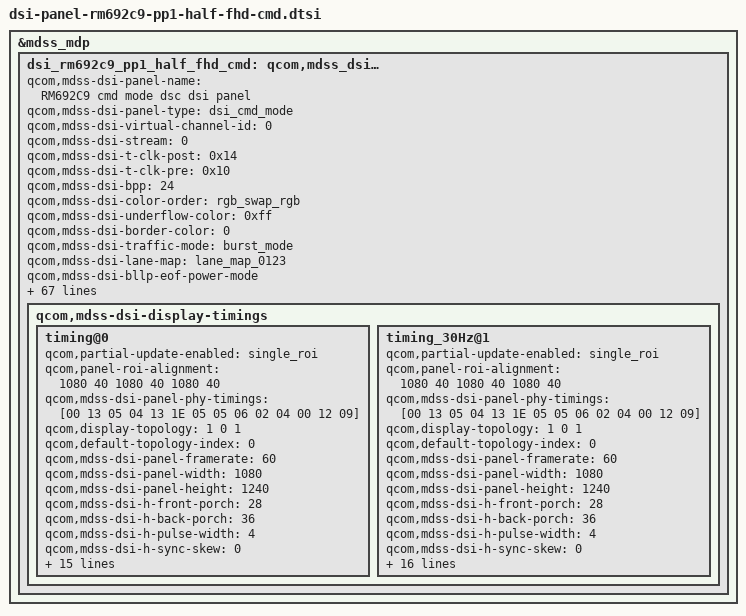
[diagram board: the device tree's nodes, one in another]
/* Copyright (c) 2014, Code Aurora Forum. All rights reserved.
 *
 * This program is free software; you can redistribute it and/or modify
 * it under the terms of the GNU General Public License version 2 and
 * only version 2 as published by the Free Software Foundation.
 *
 * This program is distributed in the hope that it will be useful,
 * but WITHOUT ANY WARRANTY; without even the implied warranty of
 * MERCHANTABILITY or FITNESS FOR A PARTICULAR PURPOSE.  See the
 * GNU General Public License for more details.
 */

&mdss_mdp {
    dsi_rm692c9_pp1_half_fhd_cmd: qcom,mdss_dsi_rm692c9_pp1_half_fhd_cmd {
		qcom,mdss-dsi-panel-name = "RM692C9 cmd mode dsc dsi panel";
		qcom,mdss-dsi-panel-type = "dsi_cmd_mode";
		qcom,mdss-dsi-virtual-channel-id = <0>;
		qcom,mdss-dsi-stream = <0>;
		qcom,mdss-dsi-t-clk-post = <0x14>;
		qcom,mdss-dsi-t-clk-pre = <0x10>;
		qcom,mdss-dsi-bpp = <24>;
		qcom,mdss-dsi-color-order = "rgb_swap_rgb";
		qcom,mdss-dsi-underflow-color = <0xff>;
		qcom,mdss-dsi-border-color = <0>;
		qcom,mdss-dsi-traffic-mode = "burst_mode";
		qcom,mdss-dsi-lane-map = "lane_map_0123";
		qcom,mdss-dsi-bllp-eof-power-mode;
		qcom,mdss-dsi-bllp-power-mode;
		qcom,mdss-dsi-lane-0-state;
		qcom,mdss-dsi-lane-1-state;
		qcom,mdss-dsi-lane-2-state;
		qcom,mdss-dsi-lane-3-state;
		qcom,mdss-dsi-reset-sequence = <1 10>, <0 2>, <1 10>;
		qcom,mdss-dsi-dma-trigger = "trigger_sw";
		qcom,mdss-dsi-mdp-trigger = "none";
		qcom,mdss-dsi-te-pin-select = <1>;
		qcom,panel-te-source = <1>;
		qcom,mdss-dsi-wr-mem-start = <0x2c>;
		qcom,mdss-dsi-wr-mem-continue = <0x3c>;
		qcom,mdss-dsi-te-dcs-command = <1>;
//		qcom,mdss-dsi-te-check-enable;
//		qcom,mdss-dsi-te-using-te-pin;
		qcom,mdss-dsi-lp11-init;
		qcom,mdss-dsi-tx-eot-append;
		qcom,dsi-sec-ctrl-num = <1>;
		qcom,dsi-sec-phy-num = <1>;
		/* qcom,dsi-select-sec-clocks = "src_byte_clk1", "src_pixel_clk1"; */
		qcom,dsi-select-sec-clocks = "mux_byte_clk1", "mux_pixel_clk1";
		qcom,ulps-enabled;
		//qcom,null-insertion-enabled;

		qcom,mdss-dsi-panel-hdr-enabled;
		qcom,mdss-dsi-panel-hdr-color-primaries = <14880 15935 32435 16555 14945 30910 7790 3415>;
		qcom,mdss-dsi-panel-peak-brightness = <5000000>;		/* max. 500nits */
		qcom,mdss-dsi-panel-blackness-level = <6134>;

		qcom,mdss-pan-physical-width-dimension = <69>;
		qcom,mdss-pan-physical-height-dimension = <80>;

		//lge,use-dim-ctrl;
		/* Brightness Map List */
		lge,blmap = <
			0
			9 9 9 9 9 9 9 9 9 9 9 10 10 10 10 11 11 11 11 12
			12 12 13 13 13 13 14 14 14 14 15 15 15 15 16 16 17 18 19 20
			22 23 24 25 26 27 28 29 31 32 33 34 35 36 37 38 40 41 42 43
			44 46 48 50 52 54 56 58 60 62 64 66 68 70 72 74 76 78 80 82
			84 87 90 93 92 95 98 101 104 107 111 114 117 120 123 126 129 132 135 138
			141 144 148 151 154 157 160 163 167 170 174 177 181 184 188 191 195 198 202 205
			209 213 216 220 223 227 230 234 237 241 244 248 251 255 260 266 271 276 281 287
			292 295 301 306 311 317 322 327 332 338 343 348 354 359 364 369 375 380 387 394
			400 407 413 420 426 433 439 446 452 459 466 472 479 485 492 498 505 511 518 524
			531 537 544 552 560 568 576 584 592 600 608 616 624 632 640 648 656 664 672 680
			688 696 704 712 720 728 736 746 756 765 775 785 795 805 814 824 834 844 854 863
			873 883 893 903 912 922 932 942 952 961 971 981 1027 1074 1120 1166 1213 1259 1305 1352
			1398 1444 1491 1537 1584 1630 1676 1723 1769 1815 1862 1908 1954 2001 2047 2047 2047 2047 2047 2047
			2047 2047 2047 2047 2047 2047 2047 2047 2047 2047 2047 2047 2047 2047 2047 2047 2047 2047 2047 2047
			2047 2047 2047 2047 2047 2047 2047 2047 2047 2047 2047 2047 2047 2047 2047 2047 2047 2047 2047 2047
			2047 2047 2047 2047 2047 2047 2047 2047 2047 2047 2047 2047 2047 2047 2047 2047 2047 2047 2047 2047
			2047 2047 2047 2047 2047 2047 2047 2047 2047 2047 2047 2047 2047 2047 2047 2047 2047 2047 2047 2047
			2047 2047 2047 2047 2047 2047 2047 2047 2047 2047 2047 2047 2047 2047 2047 2047 2047 2047 2047 2047
			2047 2047 2047 2047 2047
			>;
		lge,blmap-ve = <
			0
			9 9 9 9 9 9 9 9 9 9 9 10 10 10 10 11 11 11 11 12
			12 12 13 13 13 13 14 14 14 14 15 15 15 15 16 16 17 18 19 20
			22 23 24 25 26 27 28 29 31 32 33 34 35 36 37 38 40 41 42 43
			44 46 48 50 52 54 56 58 60 62 64 66 68 70 72 74 76 78 80 82
			84 87 90 93 92 95 98 101 104 107 111 114 117 120 123 126 129 132 135 138
			141 144 148 151 154 157 160 163 167 170 174 177 181 184 188 191 195 198 202 205
			209 213 216 220 223 227 230 234 237 241 244 248 251 255 260 266 271 276 281 287
			292 295 301 306 311 317 322 327 332 338 343 348 354 359 364 369 375 380 387 394
			400 407 413 420 426 433 439 446 452 459 466 472 479 485 492 498 505 511 518 524
			531 537 544 552 560 568 576 584 592 600 608 616 624 632 640 648 656 664 672 680
			688 696 704 712 720 728 736 746 756 765 775 785 795 805 814 824 834 844 854 863
			873 883 893 903 912 922 932 942 952 961 971 981 1027 1074 1120 1166 1213 1259 1305 1352
			1398 1444 1491 1537 1584 1630 1676 1723 1769 1815 1862 1908 1954 2001 2047 2047 2047 2047 2047 2047
			2047 2047 2047 2047 2047 2047 2047 2047 2047 2047 2047 2047 2047 2047 2047 2047 2047 2047 2047 2047
			2047 2047 2047 2047 2047 2047 2047 2047 2047 2047 2047 2047 2047 2047 2047 2047 2047 2047 2047 2047
			2047 2047 2047 2047 2047 2047 2047 2047 2047 2047 2047 2047 2047 2047 2047 2047 2047 2047 2047 2047
			2047 2047 2047 2047 2047 2047 2047 2047 2047 2047 2047 2047 2047 2047 2047 2047 2047 2047 2047 2047
			2047 2047 2047 2047 2047 2047 2047 2047 2047 2047 2047 2047 2047 2047 2047 2047 2047 2047 2047 2047
			2047 2047 2047 2047 2047
			>;
		lge,blmap-ex = <
			0
			16 16 16 16 16 16 16 16 16 20 24 28 32 37 41 45 49 53 57 61
			65 69 74 78 82 86 90 94 98 102 106 111 115 119 123 127 138 149 161 172
			183 194 205 217 228 239 250 261 273 284 295 306 317 329 340 351 362 374 385 396
			407 418 430 441 452 463 474 486 497 508 519 530 542 553 564 584 604 625 645 665
			685 706 726 746 766 787 807 827 847 867 888 908 928 948 969 989 1009 1026 1042 1059
			1075 1092 1108 1125 1141 1158 1174 1191 1207 1224 1240 1257 1273 1290 1306 1322 1337 1353 1368 1384
			1399 1415 1431 1446 1462 1477 1493 1509 1524 1540 1555 1571 1586 1602 1602 1602 1602 1602 1602 1602
			1625 1649 1672 1696 1719 1743 1766 1789 1813 1836 1860 1883 1906 1930 1953 1977 2000 2024 2047 2047
			2047 2047 2047 2047 2047 2047 2047 2047 2047 2047 2047 2047 2047 2047 2047 2047 2047 2047 2047 2047
			2047 2047 2047 2047 2047 2047 2047 2047 2047 2047 2047 2047 2047 2047 2047 2047 2047 2047 2047 2047
			2047 2047 2047 2047 2047 2047 2047 2047 2047 2047 2047 2047 2047 2047 2047 2047 2047 2047 2047 2047
			2047 2047 2047 2047 2047 2047 2047 2047 2047 2047 2047 2047 2047 2047 2047 2047 2047 2047 2047 2047
			2047 2047 2047 2047 2047 2047 2047 2047 2047 2047 2047 2047 2047 2047 2047
		>;
		lge,blmap-hdr = <
			0
			9 9 9 9 9 9 9 9 9 9 9 10 10 10 10 11 11 11 11 12
			12 12 13 13 13 13 14 14 14 14 15 15 15 15 16 16 17 18 19 20
			22 23 24 25 26 27 28 29 31 32 33 34 35 36 37 38 40 41 42 43
			44 46 48 50 52 54 56 58 60 62 64 66 68 70 72 74 76 78 80 82
			84 87 90 93 92 95 98 101 104 107 111 114 117 120 123 126 129 132 135 138
			141 144 148 151 154 157 160 163 167 170 174 177 181 184 188 191 195 198 202 205
			209 213 216 220 223 227 230 234 237 241 244 248 251 255 260 266 271 276 281 287
			292 295 301 306 311 317 322 327 332 338 343 348 354 359 364 369 375 380 387 394
			400 407 413 420 426 433 439 446 452 459 466 472 479 485 492 498 505 511 518 524
			531 537 544 552 560 568 576 584 592 600 608 616 624 632 640 648 656 664 672 680
			688 696 704 712 720 728 736 746 756 765 775 785 795 805 814 824 834 844 854 863
			873 883 893 903 912 922 932 942 952 961 971 981 1027 1074 1120 1166 1213 1259 1305 1352
			1398 1444 1491 1537 1584 1630 1676 1723 1769 1815 1862 1908 1954 2001 2047 2047 2047 2047 2047 2047
			2047 2047 2047 2047 2047 2047 2047 2047 2047 2047 2047 2047 2047 2047 2047 2047 2047 2047 2047 2047
			2047 2047 2047 2047 2047 2047 2047 2047 2047 2047 2047 2047 2047 2047 2047 2047 2047 2047 2047 2047
			2047 2047 2047 2047 2047 2047 2047 2047 2047 2047 2047 2047 2047 2047 2047 2047 2047 2047 2047 2047
			2047 2047 2047 2047 2047 2047 2047 2047 2047 2047 2047 2047 2047 2047 2047 2047 2047 2047 2047 2047
			2047 2047 2047 2047 2047 2047 2047 2047 2047 2047 2047 2047 2047 2047 2047 2047 2047 2047 2047 2047
			2047 2047 2047 2047 2047
		>;

		lge,use-color-manager;
		lge,use-color-manager-oled;

		lge,mdss-dsi-disp-ctrl-command-1 = [
			15 01 00 00 00 00 02 FE 00
		];
		lge,mdss-dsi-disp-ctrl-command-1-state = "dsi_lp_mode";
		lge,mdss-dsi-disp-ctrl-command-2 = [
			15 01 00 00 00 00 02 FE 00
		];
		lge,mdss-dsi-disp-ctrl-command-2-state = "dsi_lp_mode";

		lge,color-mode-cmds-dummy = [
			/* CE setting */
			15 00 00 00 00 00 02 FE 00
		];
		lge,color-mode-cmds-dummy-state = "dsi_lp_mode";

		//lge,use-color-manager-lut;
		lge,cm-lut-screen-mode-set-name = "def", "cin", "pho", "web", "spo", "gam", "exp";
		lge,cm-lut-screen-mode-set-cnt = <39>;
		lge,cm-lut-screen-mode-set = [
			00 0B 00 80 4F 44 20 EE 02 20 F0 CF 07 CF 04 F3 D7 CC 7D E3 07 10 FF 07 00 00 00 00 FF E7 00 03 20 00 FC 07 12 08 00
			00 0B 00 80 4F 00 FF FF 00 F0 EF C3 01 0F 0F 03 D2 EE 3F 85 07 10 53 07 08 3B 90 00 23 77 02 00 90 00 9F 06 12 00 00
			00 0B 00 80 4F F0 F0 C0 C0 22 F2 55 07 1F 00 03 43 00 EF 01 0C 10 FF 07 00 35 90 06 BD 46 02 28 80 03 46 06 12 00 00
			00 0B 00 80 4F F0 FF F0 00 FF FF D1 00 0F 0F 03 02 00 1F 05 04 10 0D 56 1E 36 F0 04 E1 36 02 1D 00 08 07 06 12 00 00
			00 0B 00 80 4F 46 22 EE 15 21 F0 CF 07 CF 04 F3 C7 CC 7D E3 07 10 2E 07 00 00 00 00 40 E7 00 03 30 00 FB 07 12 00 00
			00 0B 00 80 4F 46 40 FE 12 21 F0 CF 07 CF 04 F3 C7 CC 7D E3 07 10 7F 07 00 00 00 00 95 D7 00 03 30 00 FA 07 12 00 00
			00 0B 00 80 4F 44 20 EE 02 20 F0 CF 07 CF 04 F3 D7 CC 7D E3 07 10 FF 07 00 00 00 00 FF E7 00 03 20 00 FC 07 12 08 00
		];

		lge,cm-lut-saturation-cnt = <13>;
		lge,cm-lut-saturation = [
			00 0B 00 80 4F D9 DD DC DD DD CD 01 00
			00 0B 00 80 4F EC EF FE FF FF DF 01 00
			00 0B 00 80 4F 44 20 EE 02 20 F0 CF 07
			00 0B 00 80 4F FF 44 FF 23 44 B2 CD 0F
			00 0B 00 80 4F 1F 56 01 56 56 F3 FF 0F
		];

		lge,cm-lut-sharpness-cnt = <1>;
		lge,cm-lut-sharpness = [08 12 1C 26 30];

		lge,cm-lut-rgb-hue-cnt = <14>;
		lge,cm-lut-rgb-hue = [
			E0 25 01 F5 20 09 72 47 00 01 00 0C 50 06
			80 26 01 F5 20 09 72 A7 00 01 00 0C C0 06
			F0 26 01 F5 20 09 73 07 00 01 00 0C 40 07
			FF 26 01 F5 20 09 11 87 00 01 00 0C 3A 07
			FF 26 01 F5 20 09 7F 86 00 01 00 0C 30 07
			5A 06 01 7E 00 05 B8 47 00 00 F0 05 A4 06
			E8 06 01 7E 00 05 CF A7 00 00 F0 05 17 07
			68 07 01 7E 00 05 B9 07 00 00 F0 05 A3 07
			30 07 01 7E 00 05 00 87 00 00 F0 05 4F 07
			30 07 01 7E 00 05 84 96 00 00 F0 05 3F 07
			EB 06 00 00 00 00 FF 67 00 00 30 00 04 07
			77 07 00 00 00 00 FF 77 00 01 30 00 7C 07
			FF 07 00 00 00 00 FF E7 00 03 20 00 FC 07
			FF 07 00 00 00 00 9B 77 00 01 30 00 F4 07
			FF 07 00 00 00 00 21 87 00 01 30 00 F4 07
			35 06 0A 00 40 01 8F 67 04 43 E0 00 99 06
			C0 06 0A 00 40 01 8F 77 04 43 E0 00 10 07
			60 07 0A 00 40 01 8F E7 04 43 E0 00 B0 07
			60 07 0A 00 40 01 50 77 04 43 E0 00 AF 07
			60 07 0A 00 40 01 DE 76 04 43 E0 00 A7 07
			BA 75 12 00 F0 00 5D 67 08 7F E0 00 69 06
			4A 76 12 00 F0 00 5D 77 08 7F E0 00 DE 06
			EA 76 12 00 F0 00 5D E7 08 7F E0 00 73 07
			EA 76 12 00 F0 00 16 77 08 7F E0 00 70 07
			EA 76 12 00 F0 00 97 76 08 7F E0 00 6A 07
		];

		/* Video Enahnacement */
		lge,mdss-dsi-ve-on-command = [
			15 01 00 00 00 00 02 FE 00
		];
		lge,mdss-dsi-ve-on-command-state = "dsi_lp_mode";

		lge,mdss-dsi-ve-off-command = [
			15 01 00 00 00 00 02 FE 00
		];
		lge,mdss-dsi-ve-off-command-state = "dsi_lp_mode";

		qcom,mdss-dsi-display-timings {
			timing@0{
				qcom,partial-update-enabled = "single_roi";
				qcom,panel-roi-alignment = <1080 40 1080 40 1080 40>;
				qcom,mdss-dsi-panel-phy-timings = [00 13 05 04 13 1E 05 05 06 02 04 00 12 09];
				//qcom,mdss-dsi-panel-clockrate = <435355200>;
				qcom,display-topology = <1 0 1>;
				qcom,default-topology-index = <0>;
				qcom,mdss-dsi-panel-framerate = <60>;
				qcom,mdss-dsi-panel-width = <1080>;
				qcom,mdss-dsi-panel-height = <1240>;
				qcom,mdss-dsi-h-front-porch = <28>;
				qcom,mdss-dsi-h-back-porch = <36>;
				qcom,mdss-dsi-h-pulse-width = <4>;
				qcom,mdss-dsi-h-sync-skew = <0>;
				qcom,mdss-dsi-v-back-porch = <8>;
				qcom,mdss-dsi-v-front-porch = <16>;
				qcom,mdss-dsi-v-pulse-width = <4>;
				qcom,mdss-dsi-h-left-border = <0>;
				qcom,mdss-dsi-h-right-border = <0>;
				qcom,mdss-dsi-v-top-border = <0>;
				qcom,mdss-dsi-v-bottom-border = <0>;
				qcom,mdss-dsi-h-sync-pulse = <0>;
				//qcom,mdss-mdp-transfer-time-us = <15000>;

				qcom,mdss-dsi-on-command = [
					15 00 00 00 00 00 02 FE 40
					15 00 00 00 00 00 02 05 10
					15 00 00 00 00 00 02 06 0C
					15 00 00 00 00 00 02 08 0F
					15 00 00 00 00 00 02 09 0D
					15 00 00 00 00 00 02 0A 48
					15 00 00 00 00 00 02 0B AA
					15 00 00 00 00 00 02 0C 48
					15 00 00 00 00 00 02 0D 18
					15 00 00 00 00 00 02 0E 00
					15 00 00 00 00 00 02 0F 4D
					15 00 00 00 00 00 02 16 00
					15 00 00 00 00 00 02 20 87
					15 00 00 00 00 00 02 21 87
					15 00 00 00 00 00 02 24 00
					15 00 00 00 00 00 02 26 00
					15 00 00 00 00 00 02 28 00
					15 00 00 00 00 00 02 2A 00
					15 00 00 00 00 00 02 2D 28
					15 00 00 00 00 00 02 2F 28
					15 00 00 00 00 00 02 37 A0
					15 00 00 00 00 00 02 38 A0
					15 00 00 00 00 00 02 46 39
					15 00 00 00 00 00 02 47 39
					15 00 00 00 00 00 02 4C 08
					15 01 00 00 00 00 02 FE 00
					15 00 00 00 00 00 02 FE 40
					15 00 00 00 00 00 02 3B 20
					15 00 00 00 00 00 02 6B 40
					15 01 00 00 00 00 02 FE 00
					15 00 00 00 00 00 02 FE 70
					15 00 00 00 00 00 02 35 01
					15 01 00 00 00 00 02 FE 00
					15 00 00 00 00 00 02 FE 40
					15 00 00 00 00 00 02 4D 33
					15 00 00 00 00 00 02 4E 03
					15 00 00 00 00 00 02 6F 00
					15 00 00 00 00 00 02 A2 1A
					15 00 00 00 00 00 02 A3 1D
					15 00 00 00 00 00 02 D1 04
					15 00 00 00 00 00 02 D2 64
					15 01 00 00 00 00 02 FE 00
					15 00 00 00 00 00 02 FE 72
					15 00 00 00 00 00 02 69 FF
					15 01 00 00 00 00 02 FE 00
					15 00 00 00 00 00 02 FE 40
					15 00 00 00 00 00 02 74 51
					15 00 00 00 00 00 02 75 23
					15 00 00 00 00 00 02 80 48
					15 00 00 00 00 00 02 82 10
					15 01 00 00 00 00 02 FE 00
					15 00 00 00 00 00 02 FE 40
					15 00 00 00 00 00 02 84 01
					15 00 00 00 00 00 02 86 0F
					15 00 00 00 00 00 02 87 0D
					15 00 00 00 00 00 02 88 26
					15 00 00 00 00 00 02 89 26
					15 00 00 00 00 00 02 8B 00
					15 00 00 00 00 00 02 8C 00
					15 00 00 00 00 00 02 90 00
					15 00 00 00 00 00 02 91 06
					15 00 00 00 00 00 02 95 00
					15 00 00 00 00 00 02 9F 00
					15 00 00 00 00 00 02 A0 00
					15 01 00 00 00 00 02 FE 00
					15 00 00 00 00 00 02 FE A0
					15 00 00 00 00 00 02 45 B4
					15 01 00 00 00 00 02 FE 00
					15 00 00 00 00 00 02 FE 50
					15 00 00 00 00 00 02 E2 90
					15 00 00 00 00 00 02 E3 B0
					15 00 00 00 00 00 02 E4 1F
					15 00 00 00 00 00 02 E5 11
					15 00 00 00 00 00 02 E6 10
					15 00 00 00 00 00 02 E7 A0
					15 01 00 00 00 00 02 FE 00
					15 00 00 00 00 00 02 FE 52
					15 00 00 00 00 00 02 E2 90
					15 00 00 00 00 00 02 E3 B0
					15 00 00 00 00 00 02 E4 1F
					15 00 00 00 00 00 02 E5 11
					15 00 00 00 00 00 02 E6 10
					15 00 00 00 00 00 02 E7 A0
					15 01 00 00 00 00 02 FE 00
					15 00 00 00 00 00 02 FE 54
					15 00 00 00 00 00 02 E2 90
					15 00 00 00 00 00 02 E3 B0
					15 00 00 00 00 00 02 E4 1F
					15 00 00 00 00 00 02 E5 11
					15 00 00 00 00 00 02 E6 10
					15 00 00 00 00 00 02 E7 A0
					15 01 00 00 00 00 02 FE 00
					15 00 00 00 00 00 02 FE 56
					15 00 00 00 00 00 02 E2 90
					15 00 00 00 00 00 02 E3 B0
					15 00 00 00 00 00 02 E4 1F
					15 00 00 00 00 00 02 E5 11
					15 00 00 00 00 00 02 E6 10
					15 00 00 00 00 00 02 E7 A0
					15 01 00 00 00 00 02 FE 00
					15 00 00 00 00 00 02 FE A0
					15 00 00 00 00 00 02 0A 63
					15 01 00 00 00 00 02 FE 00
					15 00 00 00 00 00 02 FE 60
					15 00 00 00 00 00 02 EF 03
					15 00 00 00 00 00 02 F0 00
					15 00 00 00 00 00 02 F2 00
					15 00 00 00 00 00 02 F3 00
					15 00 00 00 00 00 02 F4 00
					15 01 00 00 00 00 02 FE 00
					15 00 00 00 00 00 02 FE D0
					15 00 00 00 00 00 02 43 01
					15 00 00 00 00 00 02 45 01
					15 01 00 00 00 00 02 FE 00
					15 00 00 00 00 00 02 FE 60
					15 00 00 00 00 00 02 00 84
					15 00 00 00 00 00 02 01 00
					15 00 00 00 00 00 02 02 00
					15 00 00 00 00 00 02 03 05
					15 00 00 00 00 00 02 04 00
					15 00 00 00 00 00 02 05 06
					15 00 00 00 00 00 02 06 79
					15 00 00 00 00 00 02 07 79
					15 00 00 00 00 00 02 09 C4
					15 00 00 00 00 00 02 0A 00
					15 00 00 00 00 00 02 0B 02
					15 00 00 00 00 00 02 0C 01
					15 00 00 00 00 00 02 0D 00
					15 00 00 00 00 00 02 0E 06
					15 00 00 00 00 00 02 0F 79
					15 00 00 00 00 00 02 10 0D
					15 00 00 00 00 00 02 12 C4
					15 00 00 00 00 00 02 13 00
					15 00 00 00 00 00 02 14 02
					15 00 00 00 00 00 02 15 01
					15 00 00 00 00 00 02 16 00
					15 00 00 00 00 00 02 17 03
					15 00 00 00 00 00 02 18 79
					15 00 00 00 00 00 02 19 0D
					15 00 00 00 00 00 02 1B C4
					15 00 00 00 00 00 02 1C 00
					15 00 00 00 00 00 02 1D 04
					15 00 00 00 00 00 02 1E 02
					15 00 00 00 00 00 02 1F 00
					15 00 00 00 00 00 02 20 00
					15 00 00 00 00 00 02 21 79
					15 00 00 00 00 00 02 22 00
					15 00 00 00 00 00 02 24 C4
					15 00 00 00 00 00 02 25 00
					15 00 00 00 00 00 02 26 04
					15 00 00 00 00 00 02 27 02
					15 00 00 00 00 00 02 28 00
					15 00 00 00 00 00 02 29 02
					15 00 00 00 00 00 02 2A 79
					15 00 00 00 00 00 02 2B 00
					15 00 00 00 00 00 02 95 CA
					15 00 00 00 00 00 02 96 00
					15 00 00 00 00 00 02 97 00
					15 00 00 00 00 00 02 98 00
					15 00 00 00 00 00 02 99 00
					15 00 00 00 00 00 02 9A 08
					15 00 00 00 00 00 02 9B 79
					15 00 00 00 00 00 02 9C 79
					15 00 00 00 00 00 02 9D 80
					15 01 00 00 00 00 02 FE 00
					15 00 00 00 00 00 02 FE 72
					15 00 00 00 00 00 02 21 00
					15 00 00 00 00 00 02 22 0A
					15 00 00 00 00 00 02 6D 0A
					15 00 00 00 00 00 02 B0 04
					15 00 00 00 00 00 02 B1 F4
					15 00 00 00 00 00 02 B2 04
					15 00 00 00 00 00 02 B3 F4
					15 00 00 00 00 00 02 4B B7
					15 00 00 00 00 00 02 6B B1
					15 00 00 00 00 00 02 AF FF
					15 00 00 00 00 00 02 FE 60
					15 00 00 00 00 00 02 C7 1F
					15 00 00 00 00 00 02 C8 17
					15 00 00 00 00 00 02 C9 16
					15 00 00 00 00 00 02 CA 02
					15 00 00 00 00 00 02 CB 01
					15 00 00 00 00 00 02 CC 10
					15 00 00 00 00 00 02 CD 04
					15 00 00 00 00 00 02 CE 03
					15 00 00 00 00 00 02 CF 1F
					15 00 00 00 00 00 02 D1 1F
					15 00 00 00 00 00 02 D2 1F
					15 00 00 00 00 00 02 D4 1F
					15 00 00 00 00 00 02 D5 1F
					15 00 00 00 00 00 02 DB 1F
					15 00 00 00 00 00 02 DC 17
					15 00 00 00 00 00 02 DD 16
					15 00 00 00 00 00 02 DE 02
					15 00 00 00 00 00 02 DF 01
					15 00 00 00 00 00 02 E0 00
					15 00 00 00 00 00 02 E1 04
					15 00 00 00 00 00 02 E2 03
					15 00 00 00 00 00 02 F5 80
					15 01 00 00 00 00 02 FE 00
					15 00 00 00 00 00 02 FE 70
					15 00 00 00 00 00 02 71 01
					15 00 00 00 00 00 02 72 30
					15 00 00 00 00 00 02 C3 82
					15 01 00 00 00 00 02 FE 00
					15 00 00 00 00 00 02 FE 72
					15 00 00 00 00 00 02 4B B7
					15 00 00 00 00 00 02 4C 4A
					15 00 00 00 00 00 02 4D 45
					15 00 00 00 00 00 02 52 0F
					15 00 00 00 00 00 02 6F 03
					15 00 00 00 00 00 02 8A 00
					15 00 00 00 00 00 02 8B 0A
					15 00 00 00 00 00 02 8C 15
					15 00 00 00 00 00 02 8D 18
					15 00 00 00 00 00 02 8E 4A
					15 00 00 00 00 00 02 8F 7E
					15 00 00 00 00 00 02 90 D4
					15 00 00 00 00 00 02 91 62
					15 00 00 00 00 00 02 92 28
					15 00 00 00 00 00 02 93 9A
					15 00 00 00 00 00 02 94 12
					15 00 00 00 00 00 02 95 62
					15 00 00 00 00 00 02 96 A8
					15 00 00 00 00 00 02 97 E8
					15 00 00 00 00 00 02 98 FF
					15 00 00 00 00 00 02 86 00
					15 00 00 00 00 00 02 87 40
					15 00 00 00 00 00 02 88 FA
					15 00 00 00 00 00 02 89 3F
					15 00 00 00 00 00 02 9D 11
					15 00 00 00 00 00 02 9E 16
					15 00 00 00 00 00 02 9F 17
					15 00 00 00 00 00 02 A0 18
					15 00 00 00 00 00 02 A2 21
					15 00 00 00 00 00 02 A3 36
					15 00 00 00 00 00 02 A4 5A
					15 00 00 00 00 00 02 A5 A2
					15 00 00 00 00 00 02 A6 22
					15 00 00 00 00 00 02 A7 A4
					15 00 00 00 00 00 02 A9 1F
					15 00 00 00 00 00 02 AA A1
					15 00 00 00 00 00 02 AB 1A
					15 00 00 00 00 00 02 AC 92
					15 00 00 00 00 00 02 AD FF
					15 00 00 00 00 00 02 99 00
					15 00 00 00 00 00 02 9A 00
					15 00 00 00 00 00 02 9B A5
					15 00 00 00 00 00 02 9C 3F
					15 00 00 00 00 00 02 FE 72
					15 00 00 00 00 00 02 77 00
					15 00 00 00 00 00 02 78 59
					15 00 00 00 00 00 02 79 B0
					15 00 00 00 00 00 02 7A BB
					15 00 00 00 00 00 02 7B DD
					15 00 00 00 00 00 02 7C E5
					15 00 00 00 00 00 02 7D 36
					15 00 00 00 00 00 02 7E 97
					15 00 00 00 00 00 02 7F 30
					15 00 00 00 00 00 02 80 9D
					15 00 00 00 00 00 02 81 F6
					15 00 00 00 00 00 02 82 45
					15 00 00 00 00 00 02 83 8A
					15 00 00 00 00 00 02 84 CE
					15 00 00 00 00 00 02 85 FF
					15 00 00 00 00 00 02 73 00
					15 00 00 00 00 00 02 74 50
					15 00 00 00 00 00 02 75 EA
					15 00 00 00 00 00 02 76 3F
					15 01 00 00 00 00 02 FE 00
					15 00 00 00 00 00 02 FE 74
					15 00 00 00 00 00 02 00 00
					15 00 00 00 00 00 02 01 00
					15 00 00 00 00 00 02 02 41
					15 00 00 00 00 00 02 03 07
					15 00 00 00 00 00 02 04 0F
					15 00 00 00 00 00 02 05 00
					15 00 00 00 00 00 02 06 00
					15 00 00 00 00 00 02 07 00
					15 00 00 00 00 00 02 08 00
					15 00 00 00 00 00 02 09 30
					15 00 00 00 00 00 02 0A C2
					15 00 00 00 00 00 02 0B FF
					15 00 00 00 00 00 02 0C 00
					15 00 00 00 00 00 02 0D FF
					15 01 00 00 00 00 02 FE 00
					15 00 00 00 00 00 02 FE 74
					15 00 00 00 00 00 02 0E 70
					15 00 00 00 00 00 02 0F 00
					15 00 00 00 00 00 02 10 02
					15 00 00 00 00 00 02 11 00
					15 00 00 00 00 00 02 12 00
					15 00 00 00 00 00 02 13 00
					15 00 00 00 00 00 02 14 00
					15 00 00 00 00 00 02 15 02
					15 00 00 00 00 00 02 16 06
					15 00 00 00 00 00 02 17 01
					15 00 00 00 00 00 02 18 00
					15 00 00 00 00 00 02 19 07
					15 00 00 00 00 00 02 1A 00
					15 00 00 00 00 00 02 1B 00
					15 00 00 00 00 00 02 1C 00
					15 00 00 00 00 00 02 1D 00
					15 00 00 00 00 00 02 1E 00
					15 00 00 00 00 00 02 1F 00
					15 00 00 00 00 00 02 20 00
					15 00 00 00 00 00 02 21 00
					15 00 00 00 00 00 02 22 10
					15 00 00 00 00 00 02 23 00
					15 00 00 00 00 00 02 24 F0
					15 00 00 00 00 00 02 25 FF
					15 00 00 00 00 00 02 26 FF
					15 00 00 00 00 00 02 27 FF
					15 00 00 00 00 00 02 28 FF
					15 00 00 00 00 00 02 29 00
					15 00 00 00 00 00 02 2A FF
					15 00 00 00 00 00 02 2B FF
					15 00 00 00 00 00 02 2D FF
					15 00 00 00 00 00 02 2F FF
					15 00 00 00 00 00 02 30 FF
					15 00 00 00 00 00 02 31 FF
					15 00 00 00 00 00 02 32 FF
					15 00 00 00 00 00 02 33 FF
					15 00 00 00 00 00 02 34 FF
					15 00 00 00 00 00 02 35 FF
					15 00 00 00 00 00 02 36 FF
					15 00 00 00 00 00 02 37 FF
					15 00 00 00 00 00 02 38 FF
					15 00 00 00 00 00 02 39 FF
					15 00 00 00 00 00 02 3A FF
					15 00 00 00 00 00 02 3B FF
					15 00 00 00 00 00 02 3D FF
					15 00 00 00 00 00 02 3F FF
					15 00 00 00 00 00 02 40 FF
					15 00 00 00 00 00 02 41 FF
					15 00 00 00 00 00 02 42 FF
					15 00 00 00 00 00 02 43 30
					15 00 00 00 00 00 02 44 00
					15 00 00 00 00 00 02 45 F3
					15 00 00 00 00 00 02 46 FF
					15 00 00 00 00 00 02 47 3F
					15 00 00 00 00 00 02 48 FF
					15 00 00 00 00 00 02 49 FF
					15 00 00 00 00 00 02 4A FF
					15 00 00 00 00 00 02 4B FF
					15 00 00 00 00 00 02 4C FF
					15 00 00 00 00 00 02 4D FF
					15 00 00 00 00 00 02 4E FF
					15 00 00 00 00 00 02 4F FF
					15 00 00 00 00 00 02 50 FF
					15 00 00 00 00 00 02 51 FF
					15 00 00 00 00 00 02 52 FF
					15 00 00 00 00 00 02 53 FF
					15 00 00 00 00 00 02 54 FF
					15 00 00 00 00 00 02 55 FF
					15 00 00 00 00 00 02 56 FF
					15 00 00 00 00 00 02 58 FF
					15 00 00 00 00 00 02 59 FF
					15 00 00 00 00 00 02 5A FF
					15 00 00 00 00 00 02 5B FF
					15 00 00 00 00 00 02 5C FF
					15 00 00 00 00 00 02 5D FF
					15 00 00 00 00 00 02 5E FF
					15 00 00 00 00 00 02 5F FF
					15 00 00 00 00 00 02 60 FF
					15 00 00 00 00 00 02 61 70
					15 00 00 00 00 00 02 62 00
					15 00 00 00 00 00 02 63 FF
					15 00 00 00 00 00 02 64 FF
					15 00 00 00 00 00 02 65 FF
					15 00 00 00 00 00 02 66 FF
					15 00 00 00 00 00 02 67 FF
					15 00 00 00 00 00 02 68 FF
					15 00 00 00 00 00 02 69 FF
					15 00 00 00 00 00 02 6A FF
					15 00 00 00 00 00 02 6B FF
					15 00 00 00 00 00 02 6C FF
					15 00 00 00 00 00 02 6D FF
					15 00 00 00 00 00 02 6E FF
					15 00 00 00 00 00 02 6F FF
					15 00 00 00 00 00 02 70 FF
					15 00 00 00 00 00 02 71 FF
					15 00 00 00 00 00 02 72 FF
					15 00 00 00 00 00 02 73 FF
					15 00 00 00 00 00 02 74 FF
					15 00 00 00 00 00 02 75 FF
					15 00 00 00 00 00 02 76 FF
					15 00 00 00 00 00 02 77 FF
					15 00 00 00 00 00 02 78 FF
					15 00 00 00 00 00 02 79 FF
					15 00 00 00 00 00 02 7A FF
					15 00 00 00 00 00 02 7B FF
					15 00 00 00 00 00 02 7C FF
					15 00 00 00 00 00 02 7D FF
					15 01 00 00 00 00 02 FE 00
					15 00 00 00 00 00 02 FE 90
					15 00 00 00 00 00 02 00 86
					15 00 00 00 00 00 02 01 61
					15 00 00 00 00 00 02 02 18
					15 00 00 00 00 00 02 03 24
					15 00 00 00 00 00 02 04 49
					15 00 00 00 00 00 02 05 92
					15 00 00 00 00 00 02 06 86
					15 00 00 00 00 00 02 07 61
					15 00 00 00 00 00 02 08 18
					15 00 00 00 00 00 02 09 24
					15 00 00 00 00 00 02 0A 49
					15 00 00 00 00 00 02 0B 92
					15 00 00 00 00 00 02 0C 86
					15 00 00 00 00 00 02 0D 61
					15 00 00 00 00 00 02 0E 18
					15 00 00 00 00 00 02 0F 24
					15 00 00 00 00 00 02 10 49
					15 00 00 00 00 00 02 11 92
					15 01 00 00 00 00 02 FE 00
					15 00 00 00 00 00 02 FE 40
					15 00 00 00 00 00 02 85 17
					15 01 00 00 00 00 02 FE 00
					15 00 00 00 00 00 02 FE 90
					15 00 00 00 00 00 02 14 70
					15 00 00 00 00 00 02 15 E1
					15 00 00 00 00 00 02 16 97
					15 00 00 00 00 00 02 13 31
					15 00 00 00 00 00 02 18 50
					15 00 00 00 00 00 02 19 14
					15 00 00 00 00 00 02 1A 40
					15 00 00 00 00 00 02 1B 60
					15 00 00 00 00 00 02 2A C1
					15 00 00 00 00 00 02 1C 21
					15 00 00 00 00 00 02 1D 21
					15 00 00 00 00 00 02 1E 21
					15 00 00 00 00 00 02 1F 21
					15 00 00 00 00 00 02 20 00
					15 00 00 00 00 00 02 21 00
					15 00 00 00 00 00 02 22 00
					15 00 00 00 00 00 02 2B 10
					15 00 00 00 00 00 02 2D 60
					15 00 00 00 00 00 02 2F 10
					15 00 00 00 00 00 02 30 30
					15 00 00 00 00 00 02 31 08
					15 00 00 00 00 00 02 32 60
					15 00 00 00 00 00 02 33 20
					15 00 00 00 00 00 02 34 50
					15 00 00 00 00 00 02 35 30
					15 00 00 00 00 00 02 36 40
					15 00 00 00 00 00 02 37 40
					15 00 00 00 00 00 02 38 30
					15 00 00 00 00 00 02 39 50
					15 00 00 00 00 00 02 3A 20
					15 00 00 00 00 00 02 3B 60
					15 00 00 00 00 00 02 3D 08
					15 00 00 00 00 00 02 3F 10
					15 00 00 00 00 00 02 40 60
					15 00 00 00 00 00 02 41 10
					15 00 00 00 00 00 02 42 30
					15 00 00 00 00 00 02 43 08
					15 00 00 00 00 00 02 44 60
					15 00 00 00 00 00 02 45 20
					15 00 00 00 00 00 02 46 50
					15 00 00 00 00 00 02 47 30
					15 00 00 00 00 00 02 48 40
					15 00 00 00 00 00 02 49 40
					15 00 00 00 00 00 02 4A 30
					15 00 00 00 00 00 02 4B 50
					15 00 00 00 00 00 02 4C 20
					15 00 00 00 00 00 02 4D 60
					15 00 00 00 00 00 02 4E 08
					15 00 00 00 00 00 02 4F 10
					15 00 00 00 00 00 02 50 60
					15 00 00 00 00 00 02 51 10
					15 00 00 00 00 00 02 52 15
					15 00 00 00 00 00 02 53 56
					15 00 00 00 00 00 02 54 15
					15 00 00 00 00 00 02 55 00
					15 00 00 00 00 00 02 56 15
					15 00 00 00 00 00 02 58 56
					15 00 00 00 00 00 02 59 15
					15 00 00 00 00 00 02 5A 00
					15 00 00 00 00 00 02 5B 00
					15 00 00 00 00 00 02 5C 2B
					15 00 00 00 00 00 02 5D 55
					15 00 00 00 00 00 02 5E 00
					15 00 00 00 00 00 02 5F 00
					15 00 00 00 00 00 02 60 40
					15 00 00 00 00 00 02 61 40
					15 00 00 00 00 00 02 62 00
					15 00 00 00 00 00 02 63 00
					15 00 00 00 00 00 02 64 40
					15 00 00 00 00 00 02 65 40
					15 00 00 00 00 00 02 66 00
					15 00 00 00 00 00 02 67 00
					15 00 00 00 00 00 02 68 00
					15 00 00 00 00 00 02 69 55
					15 00 00 00 00 00 02 6A 2B
					15 00 00 00 00 00 02 6B 15
					15 00 00 00 00 00 02 6C 56
					15 00 00 00 00 00 02 6D 15
					15 00 00 00 00 00 02 6E 00
					15 00 00 00 00 00 02 6F 00
					15 00 00 00 00 00 02 70 2B
					15 00 00 00 00 00 02 71 55
					15 00 00 00 00 00 02 72 00
					15 00 00 00 00 00 02 73 00
					15 00 00 00 00 00 02 74 2B
					15 00 00 00 00 00 02 75 55
					15 00 00 00 00 00 02 76 00
					15 00 00 00 00 00 02 77 00
					15 00 00 00 00 00 02 78 40
					15 00 00 00 00 00 02 79 40
					15 00 00 00 00 00 02 7A 00
					15 00 00 00 00 00 02 7B 00
					15 00 00 00 00 00 02 7C 00
					15 00 00 00 00 00 02 7D 55
					15 00 00 00 00 00 02 7E 2B
					15 00 00 00 00 00 02 7F 00
					15 00 00 00 00 00 02 80 00
					15 00 00 00 00 00 02 81 55
					15 00 00 00 00 00 02 82 2B
					15 00 00 00 00 00 02 92 15
					15 00 00 00 00 00 02 93 56
					15 00 00 00 00 00 02 94 15
					15 00 00 00 00 00 02 95 00
					15 00 00 00 00 00 02 96 15
					15 00 00 00 00 00 02 97 56
					15 00 00 00 00 00 02 98 15
					15 00 00 00 00 00 02 99 00
					15 00 00 00 00 00 02 9A 15
					15 00 00 00 00 00 02 9B 56
					15 00 00 00 00 00 02 9C 15
					15 00 00 00 00 00 02 9D 00
					15 00 00 00 00 00 02 9E 15
					15 00 00 00 00 00 02 9F 56
					15 00 00 00 00 00 02 A0 15
					15 00 00 00 00 00 02 A2 00
					15 00 00 00 00 00 02 A3 00
					15 00 00 00 00 00 02 A4 2B
					15 00 00 00 00 00 02 A5 55
					15 00 00 00 00 00 02 A6 00
					15 00 00 00 00 00 02 A7 00
					15 00 00 00 00 00 02 A9 2B
					15 00 00 00 00 00 02 AA 55
					15 00 00 00 00 00 02 AB 00
					15 00 00 00 00 00 02 AC 00
					15 00 00 00 00 00 02 AD 40
					15 00 00 00 00 00 02 AE 40
					15 00 00 00 00 00 02 AF 00
					15 00 00 00 00 00 02 B0 00
					15 00 00 00 00 00 02 B1 40
					15 00 00 00 00 00 02 B2 40
					15 00 00 00 00 00 02 B3 00
					15 00 00 00 00 00 02 B4 00
					15 00 00 00 00 00 02 B5 40
					15 00 00 00 00 00 02 B6 40
					15 00 00 00 00 00 02 B7 00
					15 00 00 00 00 00 02 B8 00
					15 00 00 00 00 00 02 B9 40
					15 00 00 00 00 00 02 BA 40
					15 00 00 00 00 00 02 BB 00
					15 00 00 00 00 00 02 BC 00
					15 00 00 00 00 00 02 BD 00
					15 00 00 00 00 00 02 BE 55
					15 00 00 00 00 00 02 BF 2B
					15 00 00 00 00 00 02 C0 00
					15 00 00 00 00 00 02 C1 00
					15 00 00 00 00 00 02 C2 55
					15 00 00 00 00 00 02 C3 2B
					15 00 00 00 00 00 02 C4 00
					15 00 00 00 00 00 02 C5 2B
					15 00 00 00 00 00 02 C6 55
					15 00 00 00 00 00 02 C7 00
					15 00 00 00 00 00 02 C8 00
					15 00 00 00 00 00 02 C9 2B
					15 00 00 00 00 00 02 CA 55
					15 00 00 00 00 00 02 CB 00
					15 00 00 00 00 00 02 CC 00
					15 00 00 00 00 00 02 CD 2B
					15 00 00 00 00 00 02 CE 55
					15 00 00 00 00 00 02 CF 00
					15 00 00 00 00 00 02 D0 00
					15 00 00 00 00 00 02 D1 2B
					15 00 00 00 00 00 02 D2 55
					15 00 00 00 00 00 02 D3 00
					15 00 00 00 00 00 02 D4 15
					15 00 00 00 00 00 02 D5 56
					15 00 00 00 00 00 02 D6 15
					15 00 00 00 00 00 02 D7 00
					15 00 00 00 00 00 02 D8 15
					15 00 00 00 00 00 02 D9 56
					15 00 00 00 00 00 02 DA 15
					15 00 00 00 00 00 02 DB 00
					15 00 00 00 00 00 02 DC 00
					15 00 00 00 00 00 02 DD 00
					15 00 00 00 00 00 02 DE 55
					15 00 00 00 00 00 02 DF 2B
					15 00 00 00 00 00 02 E0 00
					15 00 00 00 00 00 02 E1 00
					15 00 00 00 00 00 02 E2 55
					15 00 00 00 00 00 02 E3 2B
					15 00 00 00 00 00 02 E4 00
					15 00 00 00 00 00 02 E5 00
					15 00 00 00 00 00 02 E6 55
					15 00 00 00 00 00 02 E7 2B
					15 00 00 00 00 00 02 E8 00
					15 00 00 00 00 00 02 E9 00
					15 00 00 00 00 00 02 EA 55
					15 00 00 00 00 00 02 EB 2B
					15 00 00 00 00 00 02 EC 00
					15 00 00 00 00 00 02 ED 40
					15 00 00 00 00 00 02 EE 40
					15 00 00 00 00 00 02 EF 00
					15 00 00 00 00 00 02 F0 00
					15 00 00 00 00 00 02 F2 40
					15 00 00 00 00 00 02 F3 40
					15 00 00 00 00 00 02 F4 00
					15 00 00 00 00 00 02 83 04
					15 00 00 00 00 00 02 84 0C
					15 00 00 00 00 00 02 85 00
					15 00 00 00 00 00 02 86 00
					15 00 00 00 00 00 02 87 0C
					15 00 00 00 00 00 02 88 04
					15 00 00 00 00 00 02 89 00
					15 00 00 00 00 00 02 8A 0C
					15 00 00 00 00 00 02 8B 04
					15 00 00 00 00 00 02 8C 08
					15 00 00 00 00 00 02 8D 0C
					15 00 00 00 00 00 02 8E 0C
					15 00 00 00 00 00 02 8F 0C
					15 00 00 00 00 00 02 90 08
					15 00 00 00 00 00 02 91 0C
					15 01 00 00 00 00 02 FE 00
					15 00 00 00 00 00 02 FE F2
					15 00 00 00 00 00 02 12 00
					15 00 00 00 00 00 02 13 80
					15 00 00 00 00 00 02 14 00
					15 00 00 00 00 00 02 15 00
					15 00 00 00 00 00 02 16 40
					15 00 00 00 00 00 02 17 00
					15 00 00 00 00 00 02 18 00
					15 00 00 00 00 00 02 19 80
					15 00 00 00 00 00 02 1A 00
					15 00 00 00 00 00 02 1B 00
					15 00 00 00 00 00 02 1C 40
					15 00 00 00 00 00 02 1D 00
					15 00 00 00 00 00 02 1E 00
					15 00 00 00 00 00 02 1F 80
					15 00 00 00 00 00 02 20 00
					15 00 00 00 00 00 02 21 00
					15 00 00 00 00 00 02 22 40
					15 00 00 00 00 00 02 23 00
					15 01 00 00 00 00 02 FE 00
					15 00 00 00 00 00 02 FE 36
					15 00 00 00 00 00 02 A6 03
					15 00 00 00 00 00 02 00 3B
					15 00 00 00 00 00 02 01 33
					15 00 00 00 00 00 02 02 65
					15 00 00 00 00 00 02 03 FF
					15 00 00 00 00 00 02 23 00
					15 00 00 00 00 00 02 24 00
					15 00 00 00 00 00 02 25 B6
					15 00 00 00 00 00 02 26 21
					15 00 00 00 00 00 02 27 6E
					15 00 00 00 00 00 02 28 25
					15 00 00 00 00 00 02 29 32
					15 00 00 00 00 00 02 2A DD
					15 00 00 00 00 00 02 2B 94
					15 00 00 00 00 00 02 2D 54
					15 00 00 00 00 00 02 2F 4C
					15 00 00 00 00 00 02 30 03
					15 00 00 00 00 00 02 31 65
					15 00 00 00 00 00 02 32 BB
					15 00 00 00 00 00 02 33 72
					15 00 00 00 00 00 02 34 77
					15 00 00 00 00 00 02 35 2A
					15 00 00 00 00 00 02 36 E1
					15 00 00 00 00 00 02 37 98
					15 00 00 00 00 00 02 38 99
					15 00 00 00 00 00 02 39 50
					15 00 00 00 00 00 02 3A AA
					15 00 00 00 00 00 02 3B 08
					15 00 00 00 00 00 02 3D BF
					15 00 00 00 00 00 02 3F BB
					15 00 00 00 00 00 02 40 77
					15 00 00 00 00 00 02 41 C0
					15 00 00 00 00 00 02 42 CC
					15 00 00 00 00 00 02 43 08
					15 00 00 00 00 00 02 44 51
					15 00 00 00 00 00 02 45 CC
					15 00 00 00 00 00 02 46 99
					15 00 00 00 00 00 02 47 E2
					15 00 00 00 00 00 02 48 DD
					15 00 00 00 00 00 02 49 2A
					15 00 00 00 00 00 02 4A 73
					15 00 00 00 00 00 02 4B ED
					15 00 00 00 00 00 02 4C BB
					15 00 00 00 00 00 02 4D 04
					15 00 00 00 00 00 02 4E EE
					15 00 00 00 00 00 02 4F 4C
					15 00 00 00 00 00 02 50 95
					15 00 00 00 00 00 02 51 FE
					15 00 00 00 00 00 02 52 DD
					15 00 00 00 00 00 02 53 26
					15 00 00 00 00 00 02 54 FF
					15 00 00 00 00 00 02 55 6E
					15 00 00 00 00 00 02 56 B7
					15 00 00 00 00 00 02 58 0F
					15 00 00 00 00 00 02 59 FF
					15 00 00 00 00 00 02 5B AA
					15 00 00 00 00 00 02 5C 00
					15 00 00 00 00 00 02 5D 00
					15 00 00 00 00 00 02 5E 00
					15 00 00 00 00 00 02 5F 00
					15 00 00 00 00 00 02 60 AA
					15 00 00 00 00 00 02 61 00
					15 00 00 00 00 00 02 62 00
					15 00 00 00 00 00 02 63 00
					15 00 00 00 00 00 02 64 00
					15 00 00 00 00 00 02 65 AA
					15 00 00 00 00 00 02 66 00
					15 00 00 00 00 00 02 67 00
					15 00 00 00 00 00 02 68 00
					15 00 00 00 00 00 02 69 00
					15 00 00 00 00 00 02 6A 0A
					15 00 00 00 00 00 02 6B 00
					15 00 00 00 00 00 02 6C 00
					15 00 00 00 00 00 02 04 AA
					15 00 00 00 00 00 02 05 00
					15 00 00 00 00 00 02 06 00
					15 00 00 00 00 00 02 07 00
					15 00 00 00 00 00 02 08 00
					15 00 00 00 00 00 02 BB AA
					15 00 00 00 00 00 02 BC 00
					15 00 00 00 00 00 02 BD 00
					15 00 00 00 00 00 02 BE 00
					15 00 00 00 00 00 02 BF 00
					15 00 00 00 00 00 02 97 22
					15 00 00 00 00 00 02 A9 3E
					15 01 00 00 00 00 02 FE 00
					15 00 00 00 00 00 02 FE F0
					15 00 00 00 00 00 02 43 D0
					15 00 00 00 00 00 02 49 22
					15 00 00 00 00 00 02 4A D0
					15 00 00 00 00 00 02 78 01
					15 00 00 00 00 00 02 79 04
					15 00 00 00 00 00 02 7A 77
					15 00 00 00 00 00 02 7B 33
					15 01 00 00 00 00 02 FE 00
					15 00 00 00 00 00 02 FE 36
					15 00 00 00 00 00 02 A6 03
					15 00 00 00 00 00 02 AB 00
					15 00 00 00 00 00 02 AA 60
					15 00 00 00 00 00 02 AC 03
					15 01 00 00 00 00 02 FE 00
					15 00 00 00 00 00 02 FE F0
					15 00 00 00 00 00 02 47 40
					15 00 00 00 00 00 02 78 01
					15 01 00 00 00 00 02 FE 00
					15 00 00 00 00 00 02 FE D0
					15 00 00 00 00 00 02 53 01
					15 00 00 00 00 00 02 FE E0
					15 00 00 00 00 00 02 91 28
					15 00 00 00 00 00 02 92 28
					15 00 00 00 00 00 02 93 28
					15 00 00 00 00 00 02 94 25
					15 00 00 00 00 00 02 95 25
					15 00 00 00 00 00 02 96 23
					15 00 00 00 00 00 02 97 23
					15 00 00 00 00 00 02 9A 13
					15 00 00 00 00 00 02 9B 13
					15 00 00 00 00 00 02 9C 3C
					15 00 00 00 00 00 02 9D 4C
					15 00 00 00 00 00 02 9E 5B
					15 00 00 00 00 00 02 9F 7F
					15 01 00 00 00 00 02 FE 00
					15 00 00 00 00 00 02 FE 00
					15 00 00 00 00 00 02 5E 00
					15 01 00 00 00 00 02 FE 00
					15 00 00 00 00 00 02 FE E0
					15 00 00 00 00 00 02 8B 12
					15 00 00 00 00 00 02 8E 21
					15 00 00 00 00 00 02 90 14
					15 01 00 00 00 00 02 FE 00
					15 00 00 00 00 00 02 FE 70
					15 00 00 00 00 00 02 11 C0
					15 00 00 00 00 00 02 17 00
					15 01 00 00 00 00 02 FE 00
					15 00 00 00 00 00 02 FE 40
					15 00 00 00 00 00 02 9A 00
					15 01 00 00 00 00 02 FE 00
					15 00 00 00 00 00 02 FE 10
					15 00 00 00 00 00 02 CB 81
					15 01 00 00 00 00 02 FE 00
					15 00 00 00 00 00 02 FE 40
					15 00 00 00 00 00 02 98 00
					15 00 00 00 00 00 02 99 30
					15 00 00 00 00 00 02 96 01
					15 00 00 00 00 00 02 97 B1
					15 01 00 00 00 00 02 FE 00
					15 00 00 00 00 00 02 FE 10
					15 00 00 00 00 00 02 CB 81
					15 01 00 00 00 00 02 FE 00
					15 00 00 00 00 00 02 FE D0
					15 00 00 00 00 00 02 2B 83
					15 00 00 00 00 00 02 2A 15
					15 00 00 00 00 00 02 4B 21
					15 00 00 00 00 00 02 49 01
					15 00 00 00 00 00 02 50 81
					15 01 00 00 00 00 02 FE 00
					15 00 00 00 00 00 02 C2 08
					15 00 00 00 00 00 02 35 00
					39 00 00 00 00 00 03 51 00 00
					05 00 00 00 78 00 01 11
					05 00 00 00 00 00 01 29
					15 01 00 00 00 00 02 FE 00
					15 00 00 00 00 00 02 FE 50
					15 00 00 00 00 00 02 00 00
					15 00 00 00 00 00 02 02 02
					15 00 00 00 00 00 02 04 02
					15 00 00 00 00 00 02 06 03
					15 00 00 00 00 00 02 08 04
					15 00 00 00 00 00 02 0A 04
					15 00 00 00 00 00 02 0C 04
					15 00 00 00 00 00 02 0E 05
					15 00 00 00 00 00 02 10 05
					15 00 00 00 00 00 02 12 06
					15 00 00 00 00 00 02 14 06
					15 00 00 00 00 00 02 16 07
					15 00 00 00 00 00 02 18 07
					15 00 00 00 00 00 02 1A 08
					15 00 00 00 00 00 02 1C 08
					15 00 00 00 00 00 02 1E 08
					15 00 00 00 00 00 02 20 09
					15 00 00 00 00 00 02 22 09
					15 00 00 00 00 00 02 24 09
					15 00 00 00 00 00 02 26 0A
					15 00 00 00 00 00 02 28 0A
					15 00 00 00 00 00 02 2A 0A
					15 00 00 00 00 00 02 2D 0A
					15 00 00 00 00 00 02 30 0A
					15 00 00 00 00 00 02 32 0A
					15 00 00 00 00 00 02 34 0A
					15 00 00 00 00 00 02 36 0B
					15 00 00 00 00 00 02 38 0B
					15 00 00 00 00 00 02 3A 0B
					15 00 00 00 00 00 02 3D 0B
					15 00 00 00 00 00 02 40 0B
					15 00 00 00 00 00 02 48 00
					15 00 00 00 00 00 02 4A 02
					15 00 00 00 00 00 02 4C 02
					15 00 00 00 00 00 02 4E 03
					15 00 00 00 00 00 02 50 03
					15 00 00 00 00 00 02 52 04
					15 00 00 00 00 00 02 54 04
					15 00 00 00 00 00 02 56 05
					15 00 00 00 00 00 02 59 05
					15 00 00 00 00 00 02 5B 05
					15 00 00 00 00 00 02 5D 06
					15 00 00 00 00 00 02 5F 06
					15 00 00 00 00 00 02 61 07
					15 00 00 00 00 00 02 63 07
					15 00 00 00 00 00 02 65 08
					15 00 00 00 00 00 02 67 08
					15 00 00 00 00 00 02 69 08
					15 00 00 00 00 00 02 6B 09
					15 00 00 00 00 00 02 6D 09
					15 00 00 00 00 00 02 6F 09
					15 00 00 00 00 00 02 71 09
					15 00 00 00 00 00 02 73 09
					15 00 00 00 00 00 02 75 09
					15 00 00 00 00 00 02 77 0A
					15 00 00 00 00 00 02 79 0A
					15 00 00 00 00 00 02 7B 0A
					15 00 00 00 00 00 02 7D 0A
					15 00 00 00 00 00 02 7F 0A
					15 00 00 00 00 00 02 81 0A
					15 00 00 00 00 00 02 83 0A
					15 00 00 00 00 00 02 85 0A
					15 00 00 00 00 00 02 8D 00
					15 00 00 00 00 00 02 8F 03
					15 00 00 00 00 00 02 91 03
					15 00 00 00 00 00 02 93 04
					15 00 00 00 00 00 02 95 04
					15 00 00 00 00 00 02 97 04
					15 00 00 00 00 00 02 99 05
					15 00 00 00 00 00 02 9B 05
					15 00 00 00 00 00 02 9D 06
					15 00 00 00 00 00 02 9F 06
					15 00 00 00 00 00 02 A2 06
					15 00 00 00 00 00 02 A4 07
					15 00 00 00 00 00 02 A6 08
					15 00 00 00 00 00 02 A9 08
					15 00 00 00 00 00 02 AB 08
					15 00 00 00 00 00 02 AD 09
					15 00 00 00 00 00 02 AF 09
					15 00 00 00 00 00 02 B1 09
					15 00 00 00 00 00 02 B3 0A
					15 00 00 00 00 00 02 B5 0A
					15 00 00 00 00 00 02 B7 0A
					15 00 00 00 00 00 02 B9 0A
					15 00 00 00 00 00 02 BB 0A
					15 00 00 00 00 00 02 BD 0B
					15 00 00 00 00 00 02 BF 0B
					15 00 00 00 00 00 02 C1 0B
					15 00 00 00 00 00 02 C3 0B
					15 00 00 00 00 00 02 C5 0B
					15 00 00 00 00 00 02 C7 0B
					15 00 00 00 00 00 02 C9 0B
					15 00 00 00 00 00 02 CB 0B
					15 00 00 00 00 00 02 01 00
					15 00 00 00 00 00 02 03 C7
					15 00 00 00 00 00 02 05 FC
					15 00 00 00 00 00 02 07 9E
					15 00 00 00 00 00 02 09 17
					15 00 00 00 00 00 02 0B 7E
					15 00 00 00 00 00 02 0D D3
					15 00 00 00 00 00 02 0F 63
					15 00 00 00 00 00 02 11 D6
					15 00 00 00 00 00 02 13 3B
					15 00 00 00 00 00 02 15 91
					15 00 00 00 00 00 02 17 26
					15 00 00 00 00 00 02 19 A2
					15 00 00 00 00 00 02 1B 13
					15 00 00 00 00 00 02 1D 76
					15 00 00 00 00 00 02 1F D5
					15 00 00 00 00 00 02 21 30
					15 00 00 00 00 00 02 23 8D
					15 00 00 00 00 00 02 25 DF
					15 00 00 00 00 00 02 27 09
					15 00 00 00 00 00 02 29 2F
					15 00 00 00 00 00 02 2B 56
					15 00 00 00 00 00 02 2F 7E
					15 00 00 00 00 00 02 31 A2
					15 00 00 00 00 00 02 33 CA
					15 00 00 00 00 00 02 35 F2
					15 00 00 00 00 00 02 37 15
					15 00 00 00 00 00 02 39 29
					15 00 00 00 00 00 02 3B 3A
					15 00 00 00 00 00 02 3F 43
					15 00 00 00 00 00 02 41 49
					15 00 00 00 00 00 02 49 00
					15 00 00 00 00 00 02 4B D8
					15 00 00 00 00 00 02 4D EB
					15 00 00 00 00 00 02 4F 55
					15 00 00 00 00 00 02 51 BB
					15 00 00 00 00 00 02 53 1E
					15 00 00 00 00 00 02 55 72
					15 00 00 00 00 00 02 58 01
					15 00 00 00 00 00 02 5A 71
					15 00 00 00 00 00 02 5C DB
					15 00 00 00 00 00 02 5E 2D
					15 00 00 00 00 00 02 60 C0
					15 00 00 00 00 00 02 62 3B
					15 00 00 00 00 00 02 64 A9
					15 00 00 00 00 00 02 66 0D
					15 00 00 00 00 00 02 68 63
					15 00 00 00 00 00 02 6A BC
					15 00 00 00 00 00 02 6C 10
					15 00 00 00 00 00 02 6E 5B
					15 00 00 00 00 00 02 70 80
					15 00 00 00 00 00 02 72 A7
					15 00 00 00 00 00 02 74 CB
					15 00 00 00 00 00 02 76 EC
					15 00 00 00 00 00 02 78 0D
					15 00 00 00 00 00 02 7A 31
					15 00 00 00 00 00 02 7C 54
					15 00 00 00 00 00 02 7E 70
					15 00 00 00 00 00 02 80 89
					15 00 00 00 00 00 02 82 9A
					15 00 00 00 00 00 02 84 A0
					15 00 00 00 00 00 02 86 A6
					15 00 00 00 00 00 02 8E 00
					15 00 00 00 00 00 02 90 30
					15 00 00 00 00 00 02 92 5E
					15 00 00 00 00 00 02 94 04
					15 00 00 00 00 00 02 96 88
					15 00 00 00 00 00 02 98 E8
					15 00 00 00 00 00 02 9A 2E
					15 00 00 00 00 00 02 9C B5
					15 00 00 00 00 00 02 9E 2C
					15 00 00 00 00 00 02 A0 99
					15 00 00 00 00 00 02 A3 F1
					15 00 00 00 00 00 02 A5 8A
					15 00 00 00 00 00 02 A7 03
					15 00 00 00 00 00 02 AA 76
					15 00 00 00 00 00 02 AC D9
					15 00 00 00 00 00 02 AE 38
					15 00 00 00 00 00 02 B0 98
					15 00 00 00 00 00 02 B2 F3
					15 00 00 00 00 00 02 B4 43
					15 00 00 00 00 00 02 B6 6A
					15 00 00 00 00 00 02 B8 95
					15 00 00 00 00 00 02 BA B9
					15 00 00 00 00 00 02 BC E0
					15 00 00 00 00 00 02 BE 06
					15 00 00 00 00 00 02 C0 2A
					15 00 00 00 00 00 02 C2 51
					15 00 00 00 00 00 02 C4 78
					15 00 00 00 00 00 02 C6 89
					15 00 00 00 00 00 02 C8 9A
					15 00 00 00 00 00 02 CA A4
					15 00 00 00 00 00 02 CC A8
					15 01 00 00 00 00 02 FE 00
					15 00 00 00 00 00 02 FE 70
					15 00 00 00 00 00 02 71 00
					15 00 00 00 00 00 02 72 31
					15 01 00 00 00 00 02 FE 00
				];

				qcom,mdss-dsi-off-command = [
					05 01 00 00 20 00 01 28
					05 01 00 00 10 00 01 10
				];

				qcom,mdss-dsi-on-command-state = "dsi_lp_mode";
				qcom,mdss-dsi-off-command-state = "dsi_lp_mode";

				qcom,mode-control-dsi-state = "dsi_lp_mode";
			};

			timing_30Hz@1{
				qcom,partial-update-enabled = "single_roi";
				qcom,panel-roi-alignment = <1080 40 1080 40 1080 40>;
				qcom,mdss-dsi-panel-phy-timings = [00 13 05 04 13 1E 05 05 06 02 04 00 12 09];
				//qcom,mdss-dsi-panel-clockrate = <435355200>;
				qcom,display-topology = <1 0 1>;
				qcom,default-topology-index = <0>;
				qcom,mdss-dsi-panel-framerate = <60>;
				qcom,mdss-dsi-panel-width = <1080>;
				qcom,mdss-dsi-panel-height = <1240>;
				qcom,mdss-dsi-h-front-porch = <28>;
				qcom,mdss-dsi-h-back-porch = <36>;
				qcom,mdss-dsi-h-pulse-width = <4>;
				qcom,mdss-dsi-h-sync-skew = <0>;
				qcom,mdss-dsi-v-back-porch = <8>;
				qcom,mdss-dsi-v-front-porch = <16>;
				qcom,mdss-dsi-v-pulse-width = <4>;
				qcom,mdss-dsi-h-left-border = <0>;
				qcom,mdss-dsi-h-right-border = <0>;
				qcom,mdss-dsi-v-top-border = <0>;
				qcom,mdss-dsi-v-bottom-border = <0>;
				qcom,mdss-dsi-h-sync-pulse = <0>;
				//qcom,mdss-mdp-transfer-time-us = <15000>;
				lge,mdss-dsi-panel-framerate-div = <2>;

				qcom,mdss-dsi-on-command = [
					15 00 00 00 00 00 02 FE 40
					15 00 00 00 00 00 02 05 10
					15 00 00 00 00 00 02 06 0C
					15 00 00 00 00 00 02 08 0F
					15 00 00 00 00 00 02 09 0D
					15 00 00 00 00 00 02 0A 48
					15 00 00 00 00 00 02 0B AA
					15 00 00 00 00 00 02 0C 48
					15 00 00 00 00 00 02 0D 18
					15 00 00 00 00 00 02 0E 00
					15 00 00 00 00 00 02 0F 4D
					15 00 00 00 00 00 02 16 00
					15 00 00 00 00 00 02 20 87
					15 00 00 00 00 00 02 21 87
					15 00 00 00 00 00 02 24 00
					15 00 00 00 00 00 02 26 00
					15 00 00 00 00 00 02 28 00
					15 00 00 00 00 00 02 2A 00
					15 00 00 00 00 00 02 2D 28
					15 00 00 00 00 00 02 2F 28
					15 00 00 00 00 00 02 37 A0
					15 00 00 00 00 00 02 38 A0
					15 00 00 00 00 00 02 46 39
					15 00 00 00 00 00 02 47 39
					15 00 00 00 00 00 02 4C 08
					15 01 00 00 00 00 02 FE 00
					15 00 00 00 00 00 02 FE 40
					15 00 00 00 00 00 02 3B 20
					15 00 00 00 00 00 02 6B 40
					15 01 00 00 00 00 02 FE 00
					15 00 00 00 00 00 02 FE 70
					15 00 00 00 00 00 02 35 01
					15 01 00 00 00 00 02 FE 00
					15 00 00 00 00 00 02 FE 40
					15 00 00 00 00 00 02 4D 33
					15 00 00 00 00 00 02 4E 03
					15 00 00 00 00 00 02 6F 00
					15 00 00 00 00 00 02 A2 1A
					15 00 00 00 00 00 02 A3 1D
					15 00 00 00 00 00 02 D1 04
					15 00 00 00 00 00 02 D2 64
					15 01 00 00 00 00 02 FE 00
					15 00 00 00 00 00 02 FE 72
					15 00 00 00 00 00 02 69 FF
					15 01 00 00 00 00 02 FE 00
					15 00 00 00 00 00 02 FE 40
					15 00 00 00 00 00 02 74 51
					15 00 00 00 00 00 02 75 23
					15 00 00 00 00 00 02 80 48
					15 00 00 00 00 00 02 82 10
					15 01 00 00 00 00 02 FE 00
					15 00 00 00 00 00 02 FE 40
					15 00 00 00 00 00 02 84 01
					15 00 00 00 00 00 02 86 0F
					15 00 00 00 00 00 02 87 0D
					15 00 00 00 00 00 02 88 26
					15 00 00 00 00 00 02 89 26
					15 00 00 00 00 00 02 8B 00
					15 00 00 00 00 00 02 8C 00
					15 00 00 00 00 00 02 90 00
					15 00 00 00 00 00 02 91 06
					15 00 00 00 00 00 02 95 00
					15 00 00 00 00 00 02 9F 00
					15 00 00 00 00 00 02 A0 00
					15 01 00 00 00 00 02 FE 00
					15 00 00 00 00 00 02 FE A0
					15 00 00 00 00 00 02 45 B4
					15 01 00 00 00 00 02 FE 00
					15 00 00 00 00 00 02 FE 50
					15 00 00 00 00 00 02 E2 90
					15 00 00 00 00 00 02 E3 B0
					15 00 00 00 00 00 02 E4 1F
					15 00 00 00 00 00 02 E5 11
					15 00 00 00 00 00 02 E6 10
					15 00 00 00 00 00 02 E7 A0
					15 01 00 00 00 00 02 FE 00
					15 00 00 00 00 00 02 FE 52
					15 00 00 00 00 00 02 E2 90
					15 00 00 00 00 00 02 E3 B0
					15 00 00 00 00 00 02 E4 1F
					15 00 00 00 00 00 02 E5 11
					15 00 00 00 00 00 02 E6 10
					15 00 00 00 00 00 02 E7 A0
					15 01 00 00 00 00 02 FE 00
					15 00 00 00 00 00 02 FE 54
					15 00 00 00 00 00 02 E2 90
					15 00 00 00 00 00 02 E3 B0
					15 00 00 00 00 00 02 E4 1F
					15 00 00 00 00 00 02 E5 11
					15 00 00 00 00 00 02 E6 10
					15 00 00 00 00 00 02 E7 A0
					15 01 00 00 00 00 02 FE 00
					15 00 00 00 00 00 02 FE 56
					15 00 00 00 00 00 02 E2 90
					15 00 00 00 00 00 02 E3 B0
					15 00 00 00 00 00 02 E4 1F
					15 00 00 00 00 00 02 E5 11
					15 00 00 00 00 00 02 E6 10
					15 00 00 00 00 00 02 E7 A0
					15 01 00 00 00 00 02 FE 00
					15 00 00 00 00 00 02 FE A0
					15 00 00 00 00 00 02 0A 63
					15 01 00 00 00 00 02 FE 00
					15 00 00 00 00 00 02 FE 60
					15 00 00 00 00 00 02 EF 03
					15 00 00 00 00 00 02 F0 00
					15 00 00 00 00 00 02 F2 00
					15 00 00 00 00 00 02 F3 00
					15 00 00 00 00 00 02 F4 00
					15 01 00 00 00 00 02 FE 00
					15 00 00 00 00 00 02 FE D0
					15 00 00 00 00 00 02 43 01
					15 00 00 00 00 00 02 45 01
					15 01 00 00 00 00 02 FE 00
					15 00 00 00 00 00 02 FE 60
					15 00 00 00 00 00 02 00 84
					15 00 00 00 00 00 02 01 00
					15 00 00 00 00 00 02 02 00
					15 00 00 00 00 00 02 03 05
					15 00 00 00 00 00 02 04 00
					15 00 00 00 00 00 02 05 06
					15 00 00 00 00 00 02 06 79
					15 00 00 00 00 00 02 07 79
					15 00 00 00 00 00 02 09 C4
					15 00 00 00 00 00 02 0A 00
					15 00 00 00 00 00 02 0B 02
					15 00 00 00 00 00 02 0C 01
					15 00 00 00 00 00 02 0D 00
					15 00 00 00 00 00 02 0E 06
					15 00 00 00 00 00 02 0F 79
					15 00 00 00 00 00 02 10 0D
					15 00 00 00 00 00 02 12 C4
					15 00 00 00 00 00 02 13 00
					15 00 00 00 00 00 02 14 02
					15 00 00 00 00 00 02 15 01
					15 00 00 00 00 00 02 16 00
					15 00 00 00 00 00 02 17 03
					15 00 00 00 00 00 02 18 79
					15 00 00 00 00 00 02 19 0D
					15 00 00 00 00 00 02 1B C4
					15 00 00 00 00 00 02 1C 00
					15 00 00 00 00 00 02 1D 04
					15 00 00 00 00 00 02 1E 02
					15 00 00 00 00 00 02 1F 00
					15 00 00 00 00 00 02 20 00
					15 00 00 00 00 00 02 21 79
					15 00 00 00 00 00 02 22 00
					15 00 00 00 00 00 02 24 C4
					15 00 00 00 00 00 02 25 00
					15 00 00 00 00 00 02 26 04
					15 00 00 00 00 00 02 27 02
					15 00 00 00 00 00 02 28 00
					15 00 00 00 00 00 02 29 02
					15 00 00 00 00 00 02 2A 79
					15 00 00 00 00 00 02 2B 00
					15 00 00 00 00 00 02 95 CA
					15 00 00 00 00 00 02 96 00
					15 00 00 00 00 00 02 97 00
					15 00 00 00 00 00 02 98 00
					15 00 00 00 00 00 02 99 00
					15 00 00 00 00 00 02 9A 08
					15 00 00 00 00 00 02 9B 79
					15 00 00 00 00 00 02 9C 79
					15 00 00 00 00 00 02 9D 80
					15 01 00 00 00 00 02 FE 00
					15 00 00 00 00 00 02 FE 72
					15 00 00 00 00 00 02 21 00
					15 00 00 00 00 00 02 22 0A
					15 00 00 00 00 00 02 6D 0A
					15 00 00 00 00 00 02 B0 04
					15 00 00 00 00 00 02 B1 F4
					15 00 00 00 00 00 02 B2 04
					15 00 00 00 00 00 02 B3 F4
					15 00 00 00 00 00 02 4B B7
					15 00 00 00 00 00 02 6B B1
					15 00 00 00 00 00 02 AF FF
					15 00 00 00 00 00 02 FE 60
					15 00 00 00 00 00 02 C7 1F
					15 00 00 00 00 00 02 C8 17
					15 00 00 00 00 00 02 C9 16
					15 00 00 00 00 00 02 CA 02
					15 00 00 00 00 00 02 CB 01
					15 00 00 00 00 00 02 CC 10
					15 00 00 00 00 00 02 CD 04
					15 00 00 00 00 00 02 CE 03
					15 00 00 00 00 00 02 CF 1F
					15 00 00 00 00 00 02 D1 1F
					15 00 00 00 00 00 02 D2 1F
					15 00 00 00 00 00 02 D4 1F
					15 00 00 00 00 00 02 D5 1F
					15 00 00 00 00 00 02 DB 1F
					15 00 00 00 00 00 02 DC 17
					15 00 00 00 00 00 02 DD 16
					15 00 00 00 00 00 02 DE 02
					15 00 00 00 00 00 02 DF 01
					15 00 00 00 00 00 02 E0 00
					15 00 00 00 00 00 02 E1 04
					15 00 00 00 00 00 02 E2 03
					15 00 00 00 00 00 02 F5 80
					15 01 00 00 00 00 02 FE 00
					15 00 00 00 00 00 02 FE 70
					15 00 00 00 00 00 02 71 01
					15 00 00 00 00 00 02 72 30
					15 00 00 00 00 00 02 C3 82
					15 01 00 00 00 00 02 FE 00
					15 00 00 00 00 00 02 FE 72
					15 00 00 00 00 00 02 4B B7
					15 00 00 00 00 00 02 4C 4A
					15 00 00 00 00 00 02 4D 45
					15 00 00 00 00 00 02 52 0F
					15 00 00 00 00 00 02 6F 03
					15 00 00 00 00 00 02 8A 00
					15 00 00 00 00 00 02 8B 0A
					15 00 00 00 00 00 02 8C 15
					15 00 00 00 00 00 02 8D 18
					15 00 00 00 00 00 02 8E 4A
					15 00 00 00 00 00 02 8F 7E
					15 00 00 00 00 00 02 90 D4
					15 00 00 00 00 00 02 91 62
					15 00 00 00 00 00 02 92 28
					15 00 00 00 00 00 02 93 9A
					15 00 00 00 00 00 02 94 12
					15 00 00 00 00 00 02 95 62
					15 00 00 00 00 00 02 96 A8
					15 00 00 00 00 00 02 97 E8
					15 00 00 00 00 00 02 98 FF
					15 00 00 00 00 00 02 86 00
					15 00 00 00 00 00 02 87 40
					15 00 00 00 00 00 02 88 FA
					15 00 00 00 00 00 02 89 3F
					15 00 00 00 00 00 02 9D 11
					15 00 00 00 00 00 02 9E 16
					15 00 00 00 00 00 02 9F 17
					15 00 00 00 00 00 02 A0 18
					15 00 00 00 00 00 02 A2 21
					15 00 00 00 00 00 02 A3 36
					15 00 00 00 00 00 02 A4 5A
					15 00 00 00 00 00 02 A5 A2
					15 00 00 00 00 00 02 A6 22
					15 00 00 00 00 00 02 A7 A4
					15 00 00 00 00 00 02 A9 1F
					15 00 00 00 00 00 02 AA A1
					15 00 00 00 00 00 02 AB 1A
					15 00 00 00 00 00 02 AC 92
					15 00 00 00 00 00 02 AD FF
					15 00 00 00 00 00 02 99 00
					15 00 00 00 00 00 02 9A 00
					15 00 00 00 00 00 02 9B A5
					15 00 00 00 00 00 02 9C 3F
					15 00 00 00 00 00 02 FE 72
					15 00 00 00 00 00 02 77 00
					15 00 00 00 00 00 02 78 59
					15 00 00 00 00 00 02 79 B0
					15 00 00 00 00 00 02 7A BB
					15 00 00 00 00 00 02 7B DD
					15 00 00 00 00 00 02 7C E5
					15 00 00 00 00 00 02 7D 36
					15 00 00 00 00 00 02 7E 97
					15 00 00 00 00 00 02 7F 30
					15 00 00 00 00 00 02 80 9D
					15 00 00 00 00 00 02 81 F6
					15 00 00 00 00 00 02 82 45
					15 00 00 00 00 00 02 83 8A
					15 00 00 00 00 00 02 84 CE
					15 00 00 00 00 00 02 85 FF
					15 00 00 00 00 00 02 73 00
					15 00 00 00 00 00 02 74 50
					15 00 00 00 00 00 02 75 EA
					15 00 00 00 00 00 02 76 3F
					15 01 00 00 00 00 02 FE 00
					15 00 00 00 00 00 02 FE 74
					15 00 00 00 00 00 02 00 00
					15 00 00 00 00 00 02 01 00
					15 00 00 00 00 00 02 02 41
					15 00 00 00 00 00 02 03 07
					15 00 00 00 00 00 02 04 0F
					15 00 00 00 00 00 02 05 00
					15 00 00 00 00 00 02 06 00
					15 00 00 00 00 00 02 07 00
					15 00 00 00 00 00 02 08 00
					15 00 00 00 00 00 02 09 30
					15 00 00 00 00 00 02 0A C2
					15 00 00 00 00 00 02 0B FF
					15 00 00 00 00 00 02 0C 00
					15 00 00 00 00 00 02 0D FF
					15 01 00 00 00 00 02 FE 00
					15 00 00 00 00 00 02 FE 74
					15 00 00 00 00 00 02 0E 70
					15 00 00 00 00 00 02 0F 00
					15 00 00 00 00 00 02 10 02
					15 00 00 00 00 00 02 11 00
					15 00 00 00 00 00 02 12 00
					15 00 00 00 00 00 02 13 00
					15 00 00 00 00 00 02 14 00
					15 00 00 00 00 00 02 15 02
					15 00 00 00 00 00 02 16 06
					15 00 00 00 00 00 02 17 01
					15 00 00 00 00 00 02 18 00
					15 00 00 00 00 00 02 19 07
					15 00 00 00 00 00 02 1A 00
					15 00 00 00 00 00 02 1B 00
					15 00 00 00 00 00 02 1C 00
					15 00 00 00 00 00 02 1D 00
					15 00 00 00 00 00 02 1E 00
					15 00 00 00 00 00 02 1F 00
					15 00 00 00 00 00 02 20 00
					15 00 00 00 00 00 02 21 00
					15 00 00 00 00 00 02 22 10
					15 00 00 00 00 00 02 23 00
					15 00 00 00 00 00 02 24 F0
					15 00 00 00 00 00 02 25 FF
					15 00 00 00 00 00 02 26 FF
					15 00 00 00 00 00 02 27 FF
					15 00 00 00 00 00 02 28 FF
					15 00 00 00 00 00 02 29 00
					15 00 00 00 00 00 02 2A FF
					15 00 00 00 00 00 02 2B FF
					15 00 00 00 00 00 02 2D FF
					15 00 00 00 00 00 02 2F FF
					15 00 00 00 00 00 02 30 FF
					15 00 00 00 00 00 02 31 FF
					15 00 00 00 00 00 02 32 FF
					15 00 00 00 00 00 02 33 FF
					15 00 00 00 00 00 02 34 FF
					15 00 00 00 00 00 02 35 FF
					15 00 00 00 00 00 02 36 FF
					15 00 00 00 00 00 02 37 FF
					15 00 00 00 00 00 02 38 FF
					15 00 00 00 00 00 02 39 FF
					15 00 00 00 00 00 02 3A FF
					15 00 00 00 00 00 02 3B FF
					15 00 00 00 00 00 02 3D FF
					15 00 00 00 00 00 02 3F FF
					15 00 00 00 00 00 02 40 FF
					15 00 00 00 00 00 02 41 FF
					15 00 00 00 00 00 02 42 FF
					15 00 00 00 00 00 02 43 30
					15 00 00 00 00 00 02 44 00
					15 00 00 00 00 00 02 45 F3
					15 00 00 00 00 00 02 46 FF
					15 00 00 00 00 00 02 47 3F
					15 00 00 00 00 00 02 48 FF
					15 00 00 00 00 00 02 49 FF
					15 00 00 00 00 00 02 4A FF
					15 00 00 00 00 00 02 4B FF
					15 00 00 00 00 00 02 4C FF
					15 00 00 00 00 00 02 4D FF
					15 00 00 00 00 00 02 4E FF
					15 00 00 00 00 00 02 4F FF
					15 00 00 00 00 00 02 50 FF
					15 00 00 00 00 00 02 51 FF
					15 00 00 00 00 00 02 52 FF
					15 00 00 00 00 00 02 53 FF
					15 00 00 00 00 00 02 54 FF
					15 00 00 00 00 00 02 55 FF
					15 00 00 00 00 00 02 56 FF
					15 00 00 00 00 00 02 58 FF
					15 00 00 00 00 00 02 59 FF
					15 00 00 00 00 00 02 5A FF
					15 00 00 00 00 00 02 5B FF
					15 00 00 00 00 00 02 5C FF
					15 00 00 00 00 00 02 5D FF
					15 00 00 00 00 00 02 5E FF
					15 00 00 00 00 00 02 5F FF
					15 00 00 00 00 00 02 60 FF
					15 00 00 00 00 00 02 61 70
					15 00 00 00 00 00 02 62 00
					15 00 00 00 00 00 02 63 FF
					15 00 00 00 00 00 02 64 FF
					15 00 00 00 00 00 02 65 FF
					15 00 00 00 00 00 02 66 FF
					15 00 00 00 00 00 02 67 FF
					15 00 00 00 00 00 02 68 FF
					15 00 00 00 00 00 02 69 FF
					15 00 00 00 00 00 02 6A FF
					15 00 00 00 00 00 02 6B FF
					15 00 00 00 00 00 02 6C FF
					15 00 00 00 00 00 02 6D FF
					15 00 00 00 00 00 02 6E FF
					15 00 00 00 00 00 02 6F FF
					15 00 00 00 00 00 02 70 FF
					15 00 00 00 00 00 02 71 FF
					15 00 00 00 00 00 02 72 FF
					15 00 00 00 00 00 02 73 FF
					15 00 00 00 00 00 02 74 FF
					15 00 00 00 00 00 02 75 FF
					15 00 00 00 00 00 02 76 FF
					15 00 00 00 00 00 02 77 FF
					15 00 00 00 00 00 02 78 FF
					15 00 00 00 00 00 02 79 FF
					15 00 00 00 00 00 02 7A FF
					15 00 00 00 00 00 02 7B FF
					15 00 00 00 00 00 02 7C FF
					15 00 00 00 00 00 02 7D FF
					15 01 00 00 00 00 02 FE 00
					15 00 00 00 00 00 02 FE 90
					15 00 00 00 00 00 02 00 86
					15 00 00 00 00 00 02 01 61
					15 00 00 00 00 00 02 02 18
					15 00 00 00 00 00 02 03 24
					15 00 00 00 00 00 02 04 49
					15 00 00 00 00 00 02 05 92
					15 00 00 00 00 00 02 06 86
					15 00 00 00 00 00 02 07 61
					15 00 00 00 00 00 02 08 18
					15 00 00 00 00 00 02 09 24
					15 00 00 00 00 00 02 0A 49
					15 00 00 00 00 00 02 0B 92
					15 00 00 00 00 00 02 0C 86
					15 00 00 00 00 00 02 0D 61
					15 00 00 00 00 00 02 0E 18
					15 00 00 00 00 00 02 0F 24
					15 00 00 00 00 00 02 10 49
					15 00 00 00 00 00 02 11 92
					15 01 00 00 00 00 02 FE 00
					15 00 00 00 00 00 02 FE 40
					15 00 00 00 00 00 02 85 17
					15 01 00 00 00 00 02 FE 00
					15 00 00 00 00 00 02 FE 90
					15 00 00 00 00 00 02 14 70
					15 00 00 00 00 00 02 15 E1
					15 00 00 00 00 00 02 16 97
					15 00 00 00 00 00 02 13 31
					15 00 00 00 00 00 02 18 50
					15 00 00 00 00 00 02 19 14
					15 00 00 00 00 00 02 1A 40
					15 00 00 00 00 00 02 1B 60
					15 00 00 00 00 00 02 2A C1
					15 00 00 00 00 00 02 1C 21
					15 00 00 00 00 00 02 1D 21
					15 00 00 00 00 00 02 1E 21
					15 00 00 00 00 00 02 1F 21
					15 00 00 00 00 00 02 20 00
					15 00 00 00 00 00 02 21 00
					15 00 00 00 00 00 02 22 00
					15 00 00 00 00 00 02 2B 10
					15 00 00 00 00 00 02 2D 60
					15 00 00 00 00 00 02 2F 10
					15 00 00 00 00 00 02 30 30
					15 00 00 00 00 00 02 31 08
					15 00 00 00 00 00 02 32 60
					15 00 00 00 00 00 02 33 20
					15 00 00 00 00 00 02 34 50
					15 00 00 00 00 00 02 35 30
					15 00 00 00 00 00 02 36 40
					15 00 00 00 00 00 02 37 40
					15 00 00 00 00 00 02 38 30
					15 00 00 00 00 00 02 39 50
					15 00 00 00 00 00 02 3A 20
					15 00 00 00 00 00 02 3B 60
					15 00 00 00 00 00 02 3D 08
					15 00 00 00 00 00 02 3F 10
					15 00 00 00 00 00 02 40 60
					15 00 00 00 00 00 02 41 10
					15 00 00 00 00 00 02 42 30
					15 00 00 00 00 00 02 43 08
					15 00 00 00 00 00 02 44 60
					15 00 00 00 00 00 02 45 20
					15 00 00 00 00 00 02 46 50
					15 00 00 00 00 00 02 47 30
					15 00 00 00 00 00 02 48 40
					15 00 00 00 00 00 02 49 40
					15 00 00 00 00 00 02 4A 30
					15 00 00 00 00 00 02 4B 50
					15 00 00 00 00 00 02 4C 20
					15 00 00 00 00 00 02 4D 60
					15 00 00 00 00 00 02 4E 08
					15 00 00 00 00 00 02 4F 10
					15 00 00 00 00 00 02 50 60
					15 00 00 00 00 00 02 51 10
					15 00 00 00 00 00 02 52 15
					15 00 00 00 00 00 02 53 56
					15 00 00 00 00 00 02 54 15
					15 00 00 00 00 00 02 55 00
					15 00 00 00 00 00 02 56 15
					15 00 00 00 00 00 02 58 56
					15 00 00 00 00 00 02 59 15
					15 00 00 00 00 00 02 5A 00
					15 00 00 00 00 00 02 5B 00
					15 00 00 00 00 00 02 5C 2B
					15 00 00 00 00 00 02 5D 55
					15 00 00 00 00 00 02 5E 00
					15 00 00 00 00 00 02 5F 00
					15 00 00 00 00 00 02 60 40
					15 00 00 00 00 00 02 61 40
					15 00 00 00 00 00 02 62 00
					15 00 00 00 00 00 02 63 00
					15 00 00 00 00 00 02 64 40
					15 00 00 00 00 00 02 65 40
					15 00 00 00 00 00 02 66 00
					15 00 00 00 00 00 02 67 00
					15 00 00 00 00 00 02 68 00
					15 00 00 00 00 00 02 69 55
					15 00 00 00 00 00 02 6A 2B
					15 00 00 00 00 00 02 6B 15
					15 00 00 00 00 00 02 6C 56
					15 00 00 00 00 00 02 6D 15
					15 00 00 00 00 00 02 6E 00
					15 00 00 00 00 00 02 6F 00
					15 00 00 00 00 00 02 70 2B
					15 00 00 00 00 00 02 71 55
					15 00 00 00 00 00 02 72 00
					15 00 00 00 00 00 02 73 00
					15 00 00 00 00 00 02 74 2B
					15 00 00 00 00 00 02 75 55
					15 00 00 00 00 00 02 76 00
					15 00 00 00 00 00 02 77 00
					15 00 00 00 00 00 02 78 40
					15 00 00 00 00 00 02 79 40
					15 00 00 00 00 00 02 7A 00
					15 00 00 00 00 00 02 7B 00
					15 00 00 00 00 00 02 7C 00
					15 00 00 00 00 00 02 7D 55
					15 00 00 00 00 00 02 7E 2B
					15 00 00 00 00 00 02 7F 00
					15 00 00 00 00 00 02 80 00
					15 00 00 00 00 00 02 81 55
					15 00 00 00 00 00 02 82 2B
					15 00 00 00 00 00 02 92 15
					15 00 00 00 00 00 02 93 56
					15 00 00 00 00 00 02 94 15
					15 00 00 00 00 00 02 95 00
					15 00 00 00 00 00 02 96 15
					15 00 00 00 00 00 02 97 56
					15 00 00 00 00 00 02 98 15
					15 00 00 00 00 00 02 99 00
					15 00 00 00 00 00 02 9A 15
					15 00 00 00 00 00 02 9B 56
					15 00 00 00 00 00 02 9C 15
					15 00 00 00 00 00 02 9D 00
					15 00 00 00 00 00 02 9E 15
					15 00 00 00 00 00 02 9F 56
					15 00 00 00 00 00 02 A0 15
					15 00 00 00 00 00 02 A2 00
					15 00 00 00 00 00 02 A3 00
					15 00 00 00 00 00 02 A4 2B
					15 00 00 00 00 00 02 A5 55
					15 00 00 00 00 00 02 A6 00
					15 00 00 00 00 00 02 A7 00
					15 00 00 00 00 00 02 A9 2B
					15 00 00 00 00 00 02 AA 55
					15 00 00 00 00 00 02 AB 00
					15 00 00 00 00 00 02 AC 00
					15 00 00 00 00 00 02 AD 40
					15 00 00 00 00 00 02 AE 40
					15 00 00 00 00 00 02 AF 00
					15 00 00 00 00 00 02 B0 00
					15 00 00 00 00 00 02 B1 40
					15 00 00 00 00 00 02 B2 40
					15 00 00 00 00 00 02 B3 00
					15 00 00 00 00 00 02 B4 00
					15 00 00 00 00 00 02 B5 40
					15 00 00 00 00 00 02 B6 40
					15 00 00 00 00 00 02 B7 00
					15 00 00 00 00 00 02 B8 00
					15 00 00 00 00 00 02 B9 40
					15 00 00 00 00 00 02 BA 40
					15 00 00 00 00 00 02 BB 00
					15 00 00 00 00 00 02 BC 00
					15 00 00 00 00 00 02 BD 00
					15 00 00 00 00 00 02 BE 55
					15 00 00 00 00 00 02 BF 2B
					15 00 00 00 00 00 02 C0 00
					15 00 00 00 00 00 02 C1 00
					15 00 00 00 00 00 02 C2 55
					15 00 00 00 00 00 02 C3 2B
					15 00 00 00 00 00 02 C4 00
					15 00 00 00 00 00 02 C5 2B
					15 00 00 00 00 00 02 C6 55
					15 00 00 00 00 00 02 C7 00
					15 00 00 00 00 00 02 C8 00
					15 00 00 00 00 00 02 C9 2B
					15 00 00 00 00 00 02 CA 55
					15 00 00 00 00 00 02 CB 00
					15 00 00 00 00 00 02 CC 00
					15 00 00 00 00 00 02 CD 2B
					15 00 00 00 00 00 02 CE 55
					15 00 00 00 00 00 02 CF 00
					15 00 00 00 00 00 02 D0 00
					15 00 00 00 00 00 02 D1 2B
					15 00 00 00 00 00 02 D2 55
					15 00 00 00 00 00 02 D3 00
					15 00 00 00 00 00 02 D4 15
					15 00 00 00 00 00 02 D5 56
					15 00 00 00 00 00 02 D6 15
					15 00 00 00 00 00 02 D7 00
					15 00 00 00 00 00 02 D8 15
					15 00 00 00 00 00 02 D9 56
					15 00 00 00 00 00 02 DA 15
					15 00 00 00 00 00 02 DB 00
					15 00 00 00 00 00 02 DC 00
					15 00 00 00 00 00 02 DD 00
					15 00 00 00 00 00 02 DE 55
					15 00 00 00 00 00 02 DF 2B
					15 00 00 00 00 00 02 E0 00
					15 00 00 00 00 00 02 E1 00
					15 00 00 00 00 00 02 E2 55
					15 00 00 00 00 00 02 E3 2B
					15 00 00 00 00 00 02 E4 00
					15 00 00 00 00 00 02 E5 00
					15 00 00 00 00 00 02 E6 55
					15 00 00 00 00 00 02 E7 2B
					15 00 00 00 00 00 02 E8 00
					15 00 00 00 00 00 02 E9 00
					15 00 00 00 00 00 02 EA 55
					15 00 00 00 00 00 02 EB 2B
					15 00 00 00 00 00 02 EC 00
					15 00 00 00 00 00 02 ED 40
					15 00 00 00 00 00 02 EE 40
					15 00 00 00 00 00 02 EF 00
					15 00 00 00 00 00 02 F0 00
					15 00 00 00 00 00 02 F2 40
					15 00 00 00 00 00 02 F3 40
					15 00 00 00 00 00 02 F4 00
					15 00 00 00 00 00 02 83 04
					15 00 00 00 00 00 02 84 0C
					15 00 00 00 00 00 02 85 00
					15 00 00 00 00 00 02 86 00
					15 00 00 00 00 00 02 87 0C
					15 00 00 00 00 00 02 88 04
					15 00 00 00 00 00 02 89 00
					15 00 00 00 00 00 02 8A 0C
					15 00 00 00 00 00 02 8B 04
					15 00 00 00 00 00 02 8C 08
					15 00 00 00 00 00 02 8D 0C
					15 00 00 00 00 00 02 8E 0C
					15 00 00 00 00 00 02 8F 0C
					15 00 00 00 00 00 02 90 08
					15 00 00 00 00 00 02 91 0C
					15 01 00 00 00 00 02 FE 00
					15 00 00 00 00 00 02 FE F2
					15 00 00 00 00 00 02 12 00
					15 00 00 00 00 00 02 13 80
					15 00 00 00 00 00 02 14 00
					15 00 00 00 00 00 02 15 00
					15 00 00 00 00 00 02 16 40
					15 00 00 00 00 00 02 17 00
					15 00 00 00 00 00 02 18 00
					15 00 00 00 00 00 02 19 80
					15 00 00 00 00 00 02 1A 00
					15 00 00 00 00 00 02 1B 00
					15 00 00 00 00 00 02 1C 40
					15 00 00 00 00 00 02 1D 00
					15 00 00 00 00 00 02 1E 00
					15 00 00 00 00 00 02 1F 80
					15 00 00 00 00 00 02 20 00
					15 00 00 00 00 00 02 21 00
					15 00 00 00 00 00 02 22 40
					15 00 00 00 00 00 02 23 00
					15 01 00 00 00 00 02 FE 00
					15 00 00 00 00 00 02 FE 36
					15 00 00 00 00 00 02 A6 03
					15 00 00 00 00 00 02 00 3B
					15 00 00 00 00 00 02 01 33
					15 00 00 00 00 00 02 02 65
					15 00 00 00 00 00 02 03 FF
					15 00 00 00 00 00 02 23 00
					15 00 00 00 00 00 02 24 00
					15 00 00 00 00 00 02 25 B6
					15 00 00 00 00 00 02 26 21
					15 00 00 00 00 00 02 27 6E
					15 00 00 00 00 00 02 28 25
					15 00 00 00 00 00 02 29 32
					15 00 00 00 00 00 02 2A DD
					15 00 00 00 00 00 02 2B 94
					15 00 00 00 00 00 02 2D 54
					15 00 00 00 00 00 02 2F 4C
					15 00 00 00 00 00 02 30 03
					15 00 00 00 00 00 02 31 65
					15 00 00 00 00 00 02 32 BB
					15 00 00 00 00 00 02 33 72
					15 00 00 00 00 00 02 34 77
					15 00 00 00 00 00 02 35 2A
					15 00 00 00 00 00 02 36 E1
					15 00 00 00 00 00 02 37 98
					15 00 00 00 00 00 02 38 99
					15 00 00 00 00 00 02 39 50
					15 00 00 00 00 00 02 3A AA
					15 00 00 00 00 00 02 3B 08
					15 00 00 00 00 00 02 3D BF
					15 00 00 00 00 00 02 3F BB
					15 00 00 00 00 00 02 40 77
					15 00 00 00 00 00 02 41 C0
					15 00 00 00 00 00 02 42 CC
					15 00 00 00 00 00 02 43 08
					15 00 00 00 00 00 02 44 51
					15 00 00 00 00 00 02 45 CC
					15 00 00 00 00 00 02 46 99
					15 00 00 00 00 00 02 47 E2
					15 00 00 00 00 00 02 48 DD
					15 00 00 00 00 00 02 49 2A
					15 00 00 00 00 00 02 4A 73
					15 00 00 00 00 00 02 4B ED
					15 00 00 00 00 00 02 4C BB
					15 00 00 00 00 00 02 4D 04
					15 00 00 00 00 00 02 4E EE
					15 00 00 00 00 00 02 4F 4C
					15 00 00 00 00 00 02 50 95
					15 00 00 00 00 00 02 51 FE
					15 00 00 00 00 00 02 52 DD
					15 00 00 00 00 00 02 53 26
					15 00 00 00 00 00 02 54 FF
					15 00 00 00 00 00 02 55 6E
					15 00 00 00 00 00 02 56 B7
					15 00 00 00 00 00 02 58 0F
					15 00 00 00 00 00 02 59 FF
					15 00 00 00 00 00 02 5B AA
					15 00 00 00 00 00 02 5C 00
					15 00 00 00 00 00 02 5D 00
					15 00 00 00 00 00 02 5E 00
					15 00 00 00 00 00 02 5F 00
					15 00 00 00 00 00 02 60 AA
					15 00 00 00 00 00 02 61 00
					15 00 00 00 00 00 02 62 00
					15 00 00 00 00 00 02 63 00
					15 00 00 00 00 00 02 64 00
					15 00 00 00 00 00 02 65 AA
					15 00 00 00 00 00 02 66 00
					15 00 00 00 00 00 02 67 00
					15 00 00 00 00 00 02 68 00
					15 00 00 00 00 00 02 69 00
					15 00 00 00 00 00 02 6A 0A
					15 00 00 00 00 00 02 6B 00
					15 00 00 00 00 00 02 6C 00
					15 00 00 00 00 00 02 04 AA
					15 00 00 00 00 00 02 05 00
					15 00 00 00 00 00 02 06 00
					15 00 00 00 00 00 02 07 00
					15 00 00 00 00 00 02 08 00
					15 00 00 00 00 00 02 BB AA
					15 00 00 00 00 00 02 BC 00
					15 00 00 00 00 00 02 BD 00
					15 00 00 00 00 00 02 BE 00
					15 00 00 00 00 00 02 BF 00
					15 00 00 00 00 00 02 97 22
					15 00 00 00 00 00 02 A9 3E
					15 01 00 00 00 00 02 FE 00
					15 00 00 00 00 00 02 FE F0
					15 00 00 00 00 00 02 43 D0
					15 00 00 00 00 00 02 49 22
					15 00 00 00 00 00 02 4A D0
					15 00 00 00 00 00 02 78 01
					15 00 00 00 00 00 02 79 04
					15 00 00 00 00 00 02 7A 77
					15 00 00 00 00 00 02 7B 33
					15 01 00 00 00 00 02 FE 00
					15 00 00 00 00 00 02 FE 36
					15 00 00 00 00 00 02 A6 03
					15 00 00 00 00 00 02 AB 00
					15 00 00 00 00 00 02 AA 60
					15 00 00 00 00 00 02 AC 03
					15 01 00 00 00 00 02 FE 00
					15 00 00 00 00 00 02 FE F0
					15 00 00 00 00 00 02 47 40
					15 00 00 00 00 00 02 78 01
					15 01 00 00 00 00 02 FE 00
					15 00 00 00 00 00 02 FE D0
					15 00 00 00 00 00 02 53 01
					15 00 00 00 00 00 02 FE E0
					15 00 00 00 00 00 02 91 28
					15 00 00 00 00 00 02 92 28
					15 00 00 00 00 00 02 93 28
					15 00 00 00 00 00 02 94 25
					15 00 00 00 00 00 02 95 25
					15 00 00 00 00 00 02 96 23
					15 00 00 00 00 00 02 97 23
					15 00 00 00 00 00 02 9A 13
					15 00 00 00 00 00 02 9B 13
					15 00 00 00 00 00 02 9C 3C
					15 00 00 00 00 00 02 9D 4C
					15 00 00 00 00 00 02 9E 5B
					15 00 00 00 00 00 02 9F 7F
					15 01 00 00 00 00 02 FE 00
					15 00 00 00 00 00 02 FE 00
					15 00 00 00 00 00 02 5E 00
					15 01 00 00 00 00 02 FE 00
					15 00 00 00 00 00 02 FE E0
					15 00 00 00 00 00 02 8B 12
					15 00 00 00 00 00 02 8E 21
					15 00 00 00 00 00 02 90 14
					15 01 00 00 00 00 02 FE 00
					15 00 00 00 00 00 02 FE 70
					15 00 00 00 00 00 02 11 C0
					15 00 00 00 00 00 02 17 00
					15 01 00 00 00 00 02 FE 00
					15 00 00 00 00 00 02 FE 40
					15 00 00 00 00 00 02 9A 00
					15 01 00 00 00 00 02 FE 00
					15 00 00 00 00 00 02 FE 10
					15 00 00 00 00 00 02 CB 81
					15 01 00 00 00 00 02 FE 00
					15 00 00 00 00 00 02 FE 40
					15 00 00 00 00 00 02 98 00
					15 00 00 00 00 00 02 99 30
					15 00 00 00 00 00 02 96 01
					15 00 00 00 00 00 02 97 B1
					15 01 00 00 00 00 02 FE 00
					15 00 00 00 00 00 02 FE 10
					15 00 00 00 00 00 02 CB 81
					15 01 00 00 00 00 02 FE 00
					15 00 00 00 00 00 02 FE D0
					15 00 00 00 00 00 02 2B 83
					15 00 00 00 00 00 02 2A 15
					15 00 00 00 00 00 02 4B 21
					15 00 00 00 00 00 02 49 01
					15 00 00 00 00 00 02 50 81
					15 01 00 00 00 00 02 FE 00
					15 00 00 00 00 00 02 C2 08
					15 00 00 00 00 00 02 35 00
					39 00 00 00 00 00 03 51 00 00
					05 00 00 00 78 00 01 11
					05 00 00 00 00 00 01 29
					15 01 00 00 00 00 02 FE 00
					15 00 00 00 00 00 02 FE 50
					15 00 00 00 00 00 02 00 00
					15 00 00 00 00 00 02 02 02
					15 00 00 00 00 00 02 04 02
					15 00 00 00 00 00 02 06 03
					15 00 00 00 00 00 02 08 04
					15 00 00 00 00 00 02 0A 04
					15 00 00 00 00 00 02 0C 04
					15 00 00 00 00 00 02 0E 05
					15 00 00 00 00 00 02 10 05
					15 00 00 00 00 00 02 12 06
					15 00 00 00 00 00 02 14 06
					15 00 00 00 00 00 02 16 07
					15 00 00 00 00 00 02 18 07
					15 00 00 00 00 00 02 1A 08
					15 00 00 00 00 00 02 1C 08
					15 00 00 00 00 00 02 1E 08
					15 00 00 00 00 00 02 20 09
					15 00 00 00 00 00 02 22 09
					15 00 00 00 00 00 02 24 09
					15 00 00 00 00 00 02 26 0A
					15 00 00 00 00 00 02 28 0A
					15 00 00 00 00 00 02 2A 0A
					15 00 00 00 00 00 02 2D 0A
					15 00 00 00 00 00 02 30 0A
					15 00 00 00 00 00 02 32 0A
					15 00 00 00 00 00 02 34 0A
					15 00 00 00 00 00 02 36 0B
					15 00 00 00 00 00 02 38 0B
					15 00 00 00 00 00 02 3A 0B
					15 00 00 00 00 00 02 3D 0B
					15 00 00 00 00 00 02 40 0B
					15 00 00 00 00 00 02 48 00
					15 00 00 00 00 00 02 4A 02
					15 00 00 00 00 00 02 4C 02
					15 00 00 00 00 00 02 4E 03
					15 00 00 00 00 00 02 50 03
					15 00 00 00 00 00 02 52 04
					15 00 00 00 00 00 02 54 04
					15 00 00 00 00 00 02 56 05
					15 00 00 00 00 00 02 59 05
					15 00 00 00 00 00 02 5B 05
					15 00 00 00 00 00 02 5D 06
					15 00 00 00 00 00 02 5F 06
					15 00 00 00 00 00 02 61 07
					15 00 00 00 00 00 02 63 07
					15 00 00 00 00 00 02 65 08
					15 00 00 00 00 00 02 67 08
					15 00 00 00 00 00 02 69 08
					15 00 00 00 00 00 02 6B 09
					15 00 00 00 00 00 02 6D 09
					15 00 00 00 00 00 02 6F 09
					15 00 00 00 00 00 02 71 09
					15 00 00 00 00 00 02 73 09
					15 00 00 00 00 00 02 75 09
					15 00 00 00 00 00 02 77 0A
					15 00 00 00 00 00 02 79 0A
					15 00 00 00 00 00 02 7B 0A
					15 00 00 00 00 00 02 7D 0A
					15 00 00 00 00 00 02 7F 0A
					15 00 00 00 00 00 02 81 0A
					15 00 00 00 00 00 02 83 0A
					15 00 00 00 00 00 02 85 0A
					15 00 00 00 00 00 02 8D 00
					15 00 00 00 00 00 02 8F 03
					15 00 00 00 00 00 02 91 03
					15 00 00 00 00 00 02 93 04
					15 00 00 00 00 00 02 95 04
					15 00 00 00 00 00 02 97 04
					15 00 00 00 00 00 02 99 05
					15 00 00 00 00 00 02 9B 05
					15 00 00 00 00 00 02 9D 06
					15 00 00 00 00 00 02 9F 06
					15 00 00 00 00 00 02 A2 06
					15 00 00 00 00 00 02 A4 07
					15 00 00 00 00 00 02 A6 08
					15 00 00 00 00 00 02 A9 08
					15 00 00 00 00 00 02 AB 08
					15 00 00 00 00 00 02 AD 09
					15 00 00 00 00 00 02 AF 09
					15 00 00 00 00 00 02 B1 09
					15 00 00 00 00 00 02 B3 0A
					15 00 00 00 00 00 02 B5 0A
					15 00 00 00 00 00 02 B7 0A
					15 00 00 00 00 00 02 B9 0A
					15 00 00 00 00 00 02 BB 0A
					15 00 00 00 00 00 02 BD 0B
					15 00 00 00 00 00 02 BF 0B
					15 00 00 00 00 00 02 C1 0B
					15 00 00 00 00 00 02 C3 0B
					15 00 00 00 00 00 02 C5 0B
					15 00 00 00 00 00 02 C7 0B
					15 00 00 00 00 00 02 C9 0B
					15 00 00 00 00 00 02 CB 0B
					15 00 00 00 00 00 02 01 00
					15 00 00 00 00 00 02 03 C7
					15 00 00 00 00 00 02 05 FC
					15 00 00 00 00 00 02 07 9E
					15 00 00 00 00 00 02 09 17
					15 00 00 00 00 00 02 0B 7E
					15 00 00 00 00 00 02 0D D3
					15 00 00 00 00 00 02 0F 63
					15 00 00 00 00 00 02 11 D6
					15 00 00 00 00 00 02 13 3B
					15 00 00 00 00 00 02 15 91
					15 00 00 00 00 00 02 17 26
					15 00 00 00 00 00 02 19 A2
					15 00 00 00 00 00 02 1B 13
					15 00 00 00 00 00 02 1D 76
					15 00 00 00 00 00 02 1F D5
					15 00 00 00 00 00 02 21 30
					15 00 00 00 00 00 02 23 8D
					15 00 00 00 00 00 02 25 DF
					15 00 00 00 00 00 02 27 09
					15 00 00 00 00 00 02 29 2F
					15 00 00 00 00 00 02 2B 56
					15 00 00 00 00 00 02 2F 7E
					15 00 00 00 00 00 02 31 A2
					15 00 00 00 00 00 02 33 CA
					15 00 00 00 00 00 02 35 F2
					15 00 00 00 00 00 02 37 15
					15 00 00 00 00 00 02 39 29
					15 00 00 00 00 00 02 3B 3A
					15 00 00 00 00 00 02 3F 43
					15 00 00 00 00 00 02 41 49
					15 00 00 00 00 00 02 49 00
					15 00 00 00 00 00 02 4B D8
					15 00 00 00 00 00 02 4D EB
					15 00 00 00 00 00 02 4F 55
					15 00 00 00 00 00 02 51 BB
					15 00 00 00 00 00 02 53 1E
					15 00 00 00 00 00 02 55 72
					15 00 00 00 00 00 02 58 01
					15 00 00 00 00 00 02 5A 71
					15 00 00 00 00 00 02 5C DB
					15 00 00 00 00 00 02 5E 2D
					15 00 00 00 00 00 02 60 C0
					15 00 00 00 00 00 02 62 3B
					15 00 00 00 00 00 02 64 A9
					15 00 00 00 00 00 02 66 0D
					15 00 00 00 00 00 02 68 63
					15 00 00 00 00 00 02 6A BC
					15 00 00 00 00 00 02 6C 10
					15 00 00 00 00 00 02 6E 5B
					15 00 00 00 00 00 02 70 80
					15 00 00 00 00 00 02 72 A7
					15 00 00 00 00 00 02 74 CB
					15 00 00 00 00 00 02 76 EC
					15 00 00 00 00 00 02 78 0D
					15 00 00 00 00 00 02 7A 31
					15 00 00 00 00 00 02 7C 54
					15 00 00 00 00 00 02 7E 70
					15 00 00 00 00 00 02 80 89
					15 00 00 00 00 00 02 82 9A
					15 00 00 00 00 00 02 84 A0
					15 00 00 00 00 00 02 86 A6
					15 00 00 00 00 00 02 8E 00
					15 00 00 00 00 00 02 90 30
					15 00 00 00 00 00 02 92 5E
					15 00 00 00 00 00 02 94 04
					15 00 00 00 00 00 02 96 88
					15 00 00 00 00 00 02 98 E8
					15 00 00 00 00 00 02 9A 2E
					15 00 00 00 00 00 02 9C B5
					15 00 00 00 00 00 02 9E 2C
					15 00 00 00 00 00 02 A0 99
					15 00 00 00 00 00 02 A3 F1
					15 00 00 00 00 00 02 A5 8A
					15 00 00 00 00 00 02 A7 03
					15 00 00 00 00 00 02 AA 76
					15 00 00 00 00 00 02 AC D9
					15 00 00 00 00 00 02 AE 38
					15 00 00 00 00 00 02 B0 98
					15 00 00 00 00 00 02 B2 F3
					15 00 00 00 00 00 02 B4 43
					15 00 00 00 00 00 02 B6 6A
					15 00 00 00 00 00 02 B8 95
					15 00 00 00 00 00 02 BA B9
					15 00 00 00 00 00 02 BC E0
					15 00 00 00 00 00 02 BE 06
					15 00 00 00 00 00 02 C0 2A
					15 00 00 00 00 00 02 C2 51
					15 00 00 00 00 00 02 C4 78
					15 00 00 00 00 00 02 C6 89
					15 00 00 00 00 00 02 C8 9A
					15 00 00 00 00 00 02 CA A4
					15 00 00 00 00 00 02 CC A8
					15 01 00 00 00 00 02 FE 00
					15 00 00 00 00 00 02 FE 70
					15 00 00 00 00 00 02 71 00
					15 00 00 00 00 00 02 72 31
					15 01 00 00 00 00 02 FE 00
				];

				qcom,mdss-dsi-off-command = [
					05 01 00 00 20 00 01 28
					05 01 00 00 10 00 01 10
				];

				qcom,mdss-dsi-on-command-state = "dsi_lp_mode";
				qcom,mdss-dsi-off-command-state = "dsi_lp_mode";

				qcom,mode-control-dsi-state = "dsi_lp_mode";
			};

		};
	};
};
